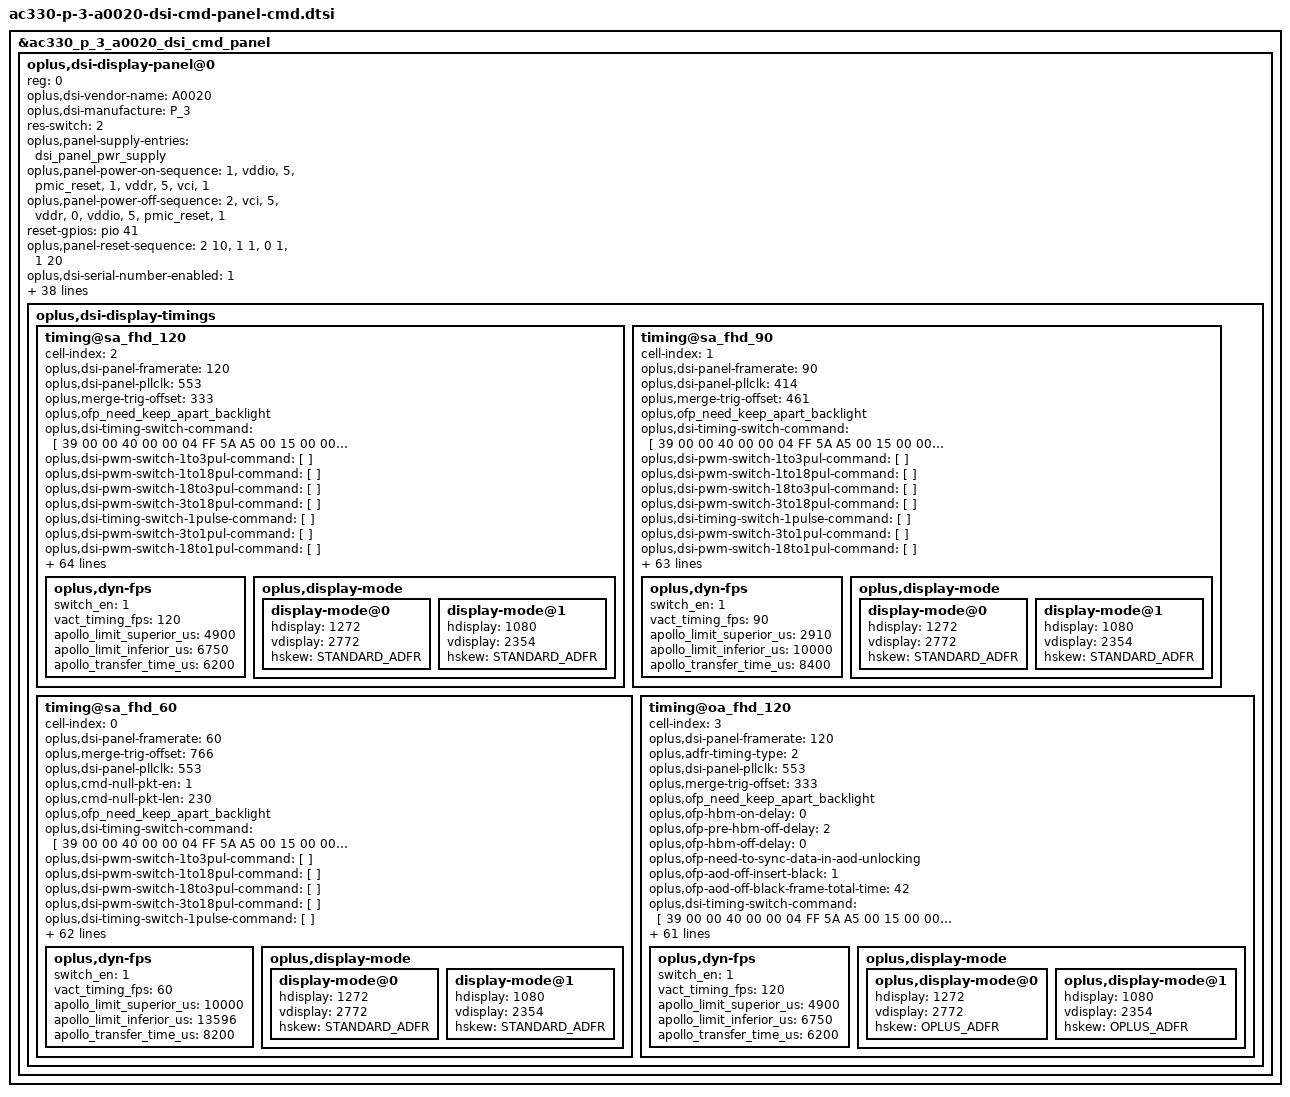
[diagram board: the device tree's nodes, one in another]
&ac330_p_3_a0020_dsi_cmd_panel {
	oplus,dsi-display-panel@0 {
		reg = <0>;
		oplus,dsi-vendor-name = "A0020";
		oplus,dsi-manufacture = "P_3";
		oplus,dsi-display-timings {
			timing@sa_fhd_120 {
				cell-index = <2>;
				oplus,dsi-panel-framerate = <120>;
				oplus,dsi-panel-pllclk = <553>;
				oplus,merge-trig-offset = <333>;
				//oplus,cmd-null-pkt-en = <1>;
				//oplus,cmd-null-pkt-len = <0>;
				/* OPLUS_FEATURE_DISPLAY_ONSCREENFINGERPRINT */
				oplus,ofp_need_keep_apart_backlight;
				/*oplus,ofp-hbm-on-delay = <0>;
				oplus,ofp-pre-hbm-off-delay = <2>;
				oplus,ofp-hbm-off-delay = <0>;
				oplus,ofp-need-to-sync-data-in-aod-unlocking;
				oplus,ofp-aod-off-insert-black = <1>;
				oplus,ofp-aod-off-black-frame-total-time = <42>;*/
				#include "ac330-p-3-a0020-dsi-cmd-panel-common.dtsi"
				oplus,dsi-timing-switch-command = [//Switch To 120Hz normal
					39 00 00 40 00 00 04 FF 5A A5 00
					15 00 00 40 00 00 02 60 00
					15 00 00 40 00 00 02 7D 00
					39 00 00 40 00 00 04 FF 5A A5 2D
					39 00 00 40 00 00 03 83 00 00
					15 00 00 40 00 00 02 F2 00
					39 00 00 00 00 00 04 FF 5A A5 00
				];
				oplus,dsi-pwm-switch-1to3pul-command = [
				];
				oplus,dsi-pwm-switch-1to18pul-command = [
				];
				oplus,dsi-pwm-switch-18to3pul-command = [
				];
				oplus,dsi-pwm-switch-3to18pul-command = [
				];
				oplus,dsi-timing-switch-1pulse-command = [
				];
				oplus,dsi-pwm-switch-3to1pul-command = [
				];
				oplus,dsi-pwm-switch-18to1pul-command = [
				];
				oplus,dsi-on-command = [
					//OTP Don’t reload
					39 00 00 00 00 00 04 FF 5A A5 08
					15 00 00 00 00 00 02 C8 62

					39 00 00 00 00 00 04 FF 5A A5 07
					15 00 00 00 00 00 02 8A 01
					39 00 00 00 00 00 03 8B 21 E0
					39 00 00 00 00 00 64 81 00 00 00 00 00 12 00 00 ab 30 80 0a d4 04 f8 00 16 02 7c 02 7c 02 00 02 59 00 20 02 2e 00 08 00 0d 04 f4 03 ed 18 00 10 f0 07 10 20 00 06 0f 0f 33 0e 1c 2a 38 46 54 62 69 70 77 79 7b 7d 7e 02 02 22 00 2a 40 2a be 3a fc 3a fa 3a f8 3b 38 3b 78 3b b6 4b b6 4b f4 4b f4 6c 34 84 74 00 00 00 00 00 00
					//Ycrcb
					15 00 00 00 00 00 02 91 03
					//VINIT3 SKIP
					39 00 00 00 00 00 04 FF 5A A5 51
					39 00 00 00 00 00 06 A0 98 A9 A8 A8 22
					15 00 00 00 00 00 02 FE 22
					15 00 00 00 00 00 02 00 00
					39 00 00 00 00 00 06 A1 A8 A7 7A 74 22
					15 00 00 00 00 00 02 FE 22
					15 00 00 00 00 00 02 00 00
					39 00 00 00 00 00 06 A2 71 6A 6A 72 22
					15 00 00 00 00 00 02 FE 22
					15 00 00 00 00 00 02 00 00
					//VINIT2 SKIP
					39 00 00 00 00 00 04 FF 5A A5 52
					39 00 00 00 00 00 06 C0 7C D2 9E 47 01
					15 00 00 00 00 00 02 FE 00
					15 00 00 00 00 00 02 00 00
					39 00 00 00 00 00 06 C1 48 48 5C 64 00
					15 00 00 00 00 00 02 FE 00
					15 00 00 00 00 00 02 00 00
					39 00 00 00 00 00 06 C2 5E 52 50 53 00
					15 00 00 00 00 00 02 FE 00
					15 00 00 00 00 00 02 00 00
					//DDIC RCN config
					39 00 00 40 00 00 04 FF 5A A5 16
					39 00 00 40 00 00 05 80 38 00 2D 00
					39 00 00 40 00 00 05 81 A7 00 52 00
					39 00 00 40 00 00 05 82 2F 00 ED 00
					39 00 00 40 00 00 05 83 A9 00 87 00
					39 00 00 40 00 00 05 84 65 00 43 00
					39 00 00 40 00 00 05 85 32 00 10 00
					39 00 00 40 00 00 05 86 1F 00 FF 00
					39 00 00 40 00 00 05 87 EE 00 DE 00
					39 00 00 40 00 00 05 88 CD 00 CC 00
					39 00 00 40 00 00 05 89 BB 00 CA 00
					39 00 00 40 00 00 05 8A BA 00 AA 00
					39 00 00 40 00 00 05 8B A9 00 99 00
					39 00 00 40 00 00 05 8C 98 00 98 00
					39 00 00 40 00 00 05 8D 97 00 88 00
					39 00 00 40 00 00 05 8E 87 00 77 00
					39 00 00 40 00 00 05 8F 77 00 77 00
					39 00 00 40 00 00 05 90 66 00 76 00
					39 00 00 40 00 00 05 91 66 00 65 00
					39 00 00 40 00 00 05 92 66 00 56 00
					39 00 00 40 00 00 05 93 55 00 55 00
					39 00 00 40 00 00 05 94 55 00 45 00
					39 00 00 40 00 00 05 95 54 00 54 00
					39 00 00 40 00 00 05 96 54 00 44 00
					39 00 00 40 00 00 05 97 44 00 44 00
					39 00 00 40 00 00 05 98 43 00 44 00
					39 00 00 40 00 00 05 99 34 00 24 00
					39 00 00 40 00 00 05 9A 33 00 43 00
					39 00 00 40 00 00 05 9B 33 00 33 00
					39 00 00 40 00 00 05 9C 33 00 32 00
					39 00 00 40 00 00 05 9D 32 00 32 00
					39 00 00 40 00 00 05 9E 32 00 32 00
					39 00 00 40 00 00 05 9F 31 00 22 00
					39 00 00 40 00 00 05 A0 32 00 22 00
					39 00 00 40 00 00 05 A1 22 00 21 00
					39 00 00 40 00 00 05 A2 21 00 22 00
					39 00 00 40 00 00 05 A3 11 00 20 00
					39 00 00 40 00 00 05 A4 22 00 12 00
					39 00 00 40 00 00 05 A5 02 00 12 00
					39 00 00 40 00 00 05 A6 12 00 01 00
					39 00 00 40 00 00 05 A7 12 00 10 00
					39 00 00 40 00 00 05 A8 11 00 21 00
					39 00 00 40 00 00 05 A9 11 00 11 00
					39 00 00 40 00 00 05 AA 10 00 11 00
					39 00 00 40 00 00 05 AB 11 00 00 00
					39 00 00 40 00 00 05 AC 10 00 01 00
					39 00 00 40 00 00 05 AD 01 00 01 00
					39 00 00 40 00 00 05 AE 10 00 11 00
					39 00 00 40 00 00 05 AF 00 00 10 00
					39 00 00 40 00 00 05 B0 00 00 10 00
					39 00 00 40 00 00 05 B1 01 00 01 00
					39 00 00 40 00 00 05 B2 00 00 10 00
					39 00 00 40 00 00 05 B3 10 00 10 00
					39 00 00 40 00 00 05 B4 01 00 00 00
					39 00 00 40 00 00 05 B5 01 00 00 00
					39 00 00 40 00 00 05 B6 00 00 00 00
					39 00 00 40 00 00 05 B7 10 00 01 00
					39 00 00 40 00 00 05 B8 00 00 10 00
					39 00 00 40 00 00 05 B9 00 00 10 00
					39 00 00 40 00 00 05 BA 00 00 00 00
					39 00 00 40 00 00 05 BB 10 00 00 00
					39 00 00 40 00 00 05 BC 00 00 10 00
					39 00 00 40 00 00 05 BD 00 00 00 00
					39 00 00 40 00 00 05 BE 00 00 00 00
					39 00 00 40 00 00 04 FF 5A A5 17
					39 00 00 40 00 00 05 80 00 00 00 00
					39 00 00 40 00 00 05 81 00 00 00 00
					39 00 00 40 00 00 05 82 00 00 00 00
					39 00 00 40 00 00 05 83 00 00 00 00
					39 00 00 40 00 00 05 84 00 00 00 00
					39 00 00 40 00 00 05 85 00 00 00 00
					39 00 00 40 00 00 05 86 00 00 00 01
					39 00 00 40 00 00 05 87 01 01 01 10
					39 00 00 40 00 00 05 88 10 11 01 10
					39 00 00 40 00 00 05 89 01 10 11 11
					39 00 00 40 00 00 05 8A 11 01 11 12
					39 00 00 40 00 00 05 8B 11 01 11 12
					39 00 00 40 00 00 05 8C 11 21 12 12
					39 00 00 40 00 00 05 8D 12 12 11 21
					39 00 00 40 00 00 05 8E 22 22 21 22
					39 00 00 40 00 00 05 8F 22 32 22 22
					39 00 00 40 00 00 05 90 22 32 32 33
					39 00 00 40 00 00 05 91 23 32 33 32
					39 00 00 40 00 00 05 92 43 33 34 33
					39 00 00 40 00 00 05 93 43 44 34 34
					39 00 00 40 00 00 05 94 44 54 44 54
					39 00 00 40 00 00 05 95 45 54 55 55
					39 00 00 40 00 00 05 96 64 65 66 56
					39 00 00 40 00 00 05 97 66 66 76 76
					39 00 00 40 00 00 05 98 77 87 87 78
					39 00 00 40 00 00 05 99 97 98 99 99
					39 00 00 40 00 00 05 9A 9A AA AB BB
					39 00 00 40 00 00 05 9B BC CC DD DE
					39 00 00 40 00 00 05 9C EF E0 01 12
					39 00 00 40 00 00 05 9D 23 54 56 79
					39 00 00 40 00 00 05 9E AC E0 13 48
					39 00 00 40 00 00 05 9F C0 61 13 48
					15 00 00 40 00 00 02 A0 8E
					15 00 00 40 00 00 02 A1 D0
					15 00 00 40 00 00 02 A2 FB
					15 00 00 40 00 00 02 A3 FC
					15 00 00 40 00 00 02 A4 2F
					15 00 00 40 00 00 02 A5 FC
					39 00 00 40 00 00 10 A6 05 04 04 03 03 04 03 03 03 03 03 02 02 02 02
					15 00 00 40 00 00 02 A8 18
					15 00 00 40 00 00 02 A9 03
					15 00 00 40 00 00 02 AA 00
					15 00 00 40 00 00 02 AB 00
					15 00 00 40 00 00 02 AC 00
					15 00 00 40 00 00 02 AD 00
					15 00 00 40 00 00 02 AE 00
					39 00 00 40 00 00 07 EC 00 00 00 00 00 00
					15 00 00 40 00 00 02 AF 04
					15 00 00 40 00 00 02 B0 0A
					15 00 00 40 00 00 02 B1 1A
					15 00 00 40 00 00 02 B2 19
					15 00 00 40 00 00 02 B3 09
					15 00 00 40 00 00 02 B4 03
					39 00 00 40 00 00 07 EC 00 00 00 00 00 00
					15 00 00 40 00 00 02 C0 00
					15 00 00 40 00 00 02 C1 00
					15 00 00 40 00 00 02 C2 00
					15 00 00 40 00 00 02 C3 00
					15 00 00 40 00 00 02 C4 00
					15 00 00 40 00 00 02 C5 00
					15 00 00 40 00 00 02 C6 00
					15 00 00 40 00 00 02 C7 33
					15 00 00 40 00 00 02 CA 08
					15 00 00 40 00 00 02 CB 80
					15 00 00 40 00 00 02 CC 05
					15 00 00 40 00 00 02 CD 03
					15 00 00 40 00 00 02 CE 08
					15 00 00 40 00 00 02 CF 05
					15 00 00 40 00 00 02 D0 7F
					15 00 00 40 00 00 02 D1 2C
					15 00 00 40 00 00 02 D2 80
					15 00 00 40 00 00 02 D3 0D
					15 00 00 40 00 00 02 D4 07
					15 00 00 40 00 00 02 D5 0E
					15 00 00 40 00 00 02 D6 03
					15 00 00 40 00 00 02 D7 14
					15 00 00 40 00 00 02 D8 A0
					15 00 00 40 00 00 02 E7 21
					15 00 00 40 00 00 02 E8 20
					15 00 00 40 00 00 02 E9 30
					15 00 00 40 00 00 02 EA 03
					39 00 00 40 00 00 03 EF 00 00
					15 00 00 40 00 00 02 F1 70
					39 00 00 00 00 00 06 F8 05 00 80 00 00

					//CTB ON
					39 00 00 00 00 00 04 FF 5A A5 31
					15 00 00 00 00 00 02 A0 A3
					//CCTC ON
					39 00 00 00 00 00 04 FF 5A A5 07
					15 00 00 00 00 00 02 E5 05

					39 00 00 00 00 00 04 FF 5A A5 06
					//scramble disable
					15 00 00 00 00 00 02 A0 00
					//set para.num
					15 00 00 00 00 00 02 AB 03
					15 00 00 00 00 00 02 AE 12
					//Page 21
					39 00 00 00 00 00 04 FF 5A A5 21
					//flash reload enable
					15 00 00 00 00 00 02 A4 18
					//Page 0
					39 00 00 00 00 00 04 FF 5A A5 00
					//Skip frame Enable
					15 00 00 00 00 00 02 5E 01
					//Normal = 120Hz
					15 00 00 00 00 00 02 60 00
					//AOD in = 30Hz
					15 00 00 00 00 00 02 61 07
					//TE On
					15 00 00 00 00 00 02 35 00
					//BC On, Dimming Off
					15 00 00 00 00 00 02 53 20
					//12-bit DBV,前两位输出normal的dbv，后两位为AOD的dbv
					39 00 00 00 00 00 05 51 00 00 07 FF
					39 00 00 00 00 00 04 FF 5A A5 20
					15 00 00 00 00 00 02 BC 07
					39 00 00 40 00 00 04 FF 5A A5 2D
					39 00 00 40 00 00 03 83 77 00
					15 00 00 40 00 00 02 97 03
					39 00 00 40 00 00 03 98 03 00
					39 00 00 40 00 00 03 99 0B 00
					39 00 00 40 00 00 03 9A 17 00
					39 00 00 40 00 00 03 9B 77 00
					39 00 00 40 00 00 05 A0 00 01 00 00
					39 00 00 40 00 00 05 A1 02 00 00 00
					39 00 00 40 00 00 03 83 00 00
					//spr config
					39 00 00 40 00 00 04 FF 5A A5 14
					39 00 00 40 00 00 07 A3 00 04 00 04 70 80
					//LVD on
					39 00 00 00 00 00 04 FF 5A A5 05
					15 00 00 00 00 00 02 83 03
					15 00 00 00 00 00 02 84 03
					15 00 00 00 00 00 02 AA 94
					15 00 00 00 00 00 02 AB C9
					15 00 00 00 00 00 02 AC 05
					39 00 00 00 00 00 04 FF 5A A5 08
					15 00 00 00 00 00 02 B0 55
					39 00 00 00 00 00 04 FF 5A A5 1C
					39 00 00 00 00 00 03 FD 00 94
					15 00 00 00 00 00 02 E1 A2
					39 00 00 00 00 00 03 FD 00 00
					39 00 00 00 00 00 04 FF 5A A5 08
					15 00 00 00 00 00 02 B0 00
					//page 00
					39 00 00 00 00 00 04 FF 5A A5 00

					15 00 00 00 78 00 02 11 00

					15 00 00 00 14 00 02 29 00
				];

				oplus,dsi-on-t0-command = [
					//OTP Don’t reload
					39 00 00 00 00 00 04 FF 5A A5 08
					15 00 00 00 00 00 02 C8 62

					39 00 00 00 00 00 04 FF 5A A5 07
					15 00 00 00 00 00 02 8A 01
					39 00 00 00 00 00 03 8B 21 E0
					39 00 00 00 00 00 64 81 00 00 00 00 00 12 00 00 ab 30 80 0a d4 04 f8 00 16 02 7c 02 7c 02 00 02 59 00 20 02 2e 00 08 00 0d 04 f4 03 ed 18 00 10 f0 07 10 20 00 06 0f 0f 33 0e 1c 2a 38 46 54 62 69 70 77 79 7b 7d 7e 02 02 22 00 2a 40 2a be 3a fc 3a fa 3a f8 3b 38 3b 78 3b b6 4b b6 4b f4 4b f4 6c 34 84 74 00 00 00 00 00 00
					//Ycrcb
					15 00 00 00 00 00 02 91 03
					//VINIT3 SKIP
					39 00 00 00 00 00 04 FF 5A A5 51
					39 00 00 00 00 00 06 A0 98 A9 A8 A8 22
					15 00 00 00 00 00 02 FE 22
					15 00 00 00 00 00 02 00 00
					39 00 00 00 00 00 06 A1 A8 A7 7A 74 22
					15 00 00 00 00 00 02 FE 22
					15 00 00 00 00 00 02 00 00
					39 00 00 00 00 00 06 A2 71 6A 6A 72 22
					15 00 00 00 00 00 02 FE 22
					15 00 00 00 00 00 02 00 00
					//VINIT2 SKIP
					39 00 00 00 00 00 04 FF 5A A5 52
					39 00 00 00 00 00 06 C0 7C D2 9E 47 01
					15 00 00 00 00 00 02 FE 00
					15 00 00 00 00 00 02 00 00
					39 00 00 00 00 00 06 C1 48 48 5C 64 00
					15 00 00 00 00 00 02 FE 00
					15 00 00 00 00 00 02 00 00
					39 00 00 00 00 00 06 C2 5E 52 50 53 00
					15 00 00 00 00 00 02 FE 00
					15 00 00 00 00 00 02 00 00
					//DDIC RCN config
					39 00 00 40 00 00 04 FF 5A A5 16
					39 00 00 40 00 00 05 80 38 00 2D 00
					39 00 00 40 00 00 05 81 A7 00 52 00
					39 00 00 40 00 00 05 82 2F 00 ED 00
					39 00 00 40 00 00 05 83 A9 00 87 00
					39 00 00 40 00 00 05 84 65 00 43 00
					39 00 00 40 00 00 05 85 32 00 10 00
					39 00 00 40 00 00 05 86 1F 00 FF 00
					39 00 00 40 00 00 05 87 EE 00 DE 00
					39 00 00 40 00 00 05 88 CD 00 CC 00
					39 00 00 40 00 00 05 89 BB 00 CA 00
					39 00 00 40 00 00 05 8A BA 00 AA 00
					39 00 00 40 00 00 05 8B A9 00 99 00
					39 00 00 40 00 00 05 8C 98 00 98 00
					39 00 00 40 00 00 05 8D 97 00 88 00
					39 00 00 40 00 00 05 8E 87 00 77 00
					39 00 00 40 00 00 05 8F 77 00 77 00
					39 00 00 40 00 00 05 90 66 00 76 00
					39 00 00 40 00 00 05 91 66 00 65 00
					39 00 00 40 00 00 05 92 66 00 56 00
					39 00 00 40 00 00 05 93 55 00 55 00
					39 00 00 40 00 00 05 94 55 00 45 00
					39 00 00 40 00 00 05 95 54 00 54 00
					39 00 00 40 00 00 05 96 54 00 44 00
					39 00 00 40 00 00 05 97 44 00 44 00
					39 00 00 40 00 00 05 98 43 00 44 00
					39 00 00 40 00 00 05 99 34 00 24 00
					39 00 00 40 00 00 05 9A 33 00 43 00
					39 00 00 40 00 00 05 9B 33 00 33 00
					39 00 00 40 00 00 05 9C 33 00 32 00
					39 00 00 40 00 00 05 9D 32 00 32 00
					39 00 00 40 00 00 05 9E 32 00 32 00
					39 00 00 40 00 00 05 9F 31 00 22 00
					39 00 00 40 00 00 05 A0 32 00 22 00
					39 00 00 40 00 00 05 A1 22 00 21 00
					39 00 00 40 00 00 05 A2 21 00 22 00
					39 00 00 40 00 00 05 A3 11 00 20 00
					39 00 00 40 00 00 05 A4 22 00 12 00
					39 00 00 40 00 00 05 A5 02 00 12 00
					39 00 00 40 00 00 05 A6 12 00 01 00
					39 00 00 40 00 00 05 A7 12 00 10 00
					39 00 00 40 00 00 05 A8 11 00 21 00
					39 00 00 40 00 00 05 A9 11 00 11 00
					39 00 00 40 00 00 05 AA 10 00 11 00
					39 00 00 40 00 00 05 AB 11 00 00 00
					39 00 00 40 00 00 05 AC 10 00 01 00
					39 00 00 40 00 00 05 AD 01 00 01 00
					39 00 00 40 00 00 05 AE 10 00 11 00
					39 00 00 40 00 00 05 AF 00 00 10 00
					39 00 00 40 00 00 05 B0 00 00 10 00
					39 00 00 40 00 00 05 B1 01 00 01 00
					39 00 00 40 00 00 05 B2 00 00 10 00
					39 00 00 40 00 00 05 B3 10 00 10 00
					39 00 00 40 00 00 05 B4 01 00 00 00
					39 00 00 40 00 00 05 B5 01 00 00 00
					39 00 00 40 00 00 05 B6 00 00 00 00
					39 00 00 40 00 00 05 B7 10 00 01 00
					39 00 00 40 00 00 05 B8 00 00 10 00
					39 00 00 40 00 00 05 B9 00 00 10 00
					39 00 00 40 00 00 05 BA 00 00 00 00
					39 00 00 40 00 00 05 BB 10 00 00 00
					39 00 00 40 00 00 05 BC 00 00 10 00
					39 00 00 40 00 00 05 BD 00 00 00 00
					39 00 00 40 00 00 05 BE 00 00 00 00
					39 00 00 40 00 00 04 FF 5A A5 17
					39 00 00 40 00 00 05 80 00 00 00 00
					39 00 00 40 00 00 05 81 00 00 00 00
					39 00 00 40 00 00 05 82 00 00 00 00
					39 00 00 40 00 00 05 83 00 00 00 00
					39 00 00 40 00 00 05 84 00 00 00 00
					39 00 00 40 00 00 05 85 00 00 00 00
					39 00 00 40 00 00 05 86 00 00 00 01
					39 00 00 40 00 00 05 87 01 01 01 10
					39 00 00 40 00 00 05 88 10 11 01 10
					39 00 00 40 00 00 05 89 01 10 11 11
					39 00 00 40 00 00 05 8A 11 01 11 12
					39 00 00 40 00 00 05 8B 11 01 11 12
					39 00 00 40 00 00 05 8C 11 21 12 12
					39 00 00 40 00 00 05 8D 12 12 11 21
					39 00 00 40 00 00 05 8E 22 22 21 22
					39 00 00 40 00 00 05 8F 22 32 22 22
					39 00 00 40 00 00 05 90 22 32 32 33
					39 00 00 40 00 00 05 91 23 32 33 32
					39 00 00 40 00 00 05 92 43 33 34 33
					39 00 00 40 00 00 05 93 43 44 34 34
					39 00 00 40 00 00 05 94 44 54 44 54
					39 00 00 40 00 00 05 95 45 54 55 55
					39 00 00 40 00 00 05 96 64 65 66 56
					39 00 00 40 00 00 05 97 66 66 76 76
					39 00 00 40 00 00 05 98 77 87 87 78
					39 00 00 40 00 00 05 99 97 98 99 99
					39 00 00 40 00 00 05 9A 9A AA AB BB
					39 00 00 40 00 00 05 9B BC CC DD DE
					39 00 00 40 00 00 05 9C EF E0 01 12
					39 00 00 40 00 00 05 9D 23 54 56 79
					39 00 00 40 00 00 05 9E AC E0 13 48
					39 00 00 40 00 00 05 9F C0 61 13 48
					15 00 00 40 00 00 02 A0 8E
					15 00 00 40 00 00 02 A1 D0
					15 00 00 40 00 00 02 A2 FB
					15 00 00 40 00 00 02 A3 FC
					15 00 00 40 00 00 02 A4 2F
					15 00 00 40 00 00 02 A5 FC
					39 00 00 40 00 00 10 A6 05 04 04 03 03 04 03 03 03 03 03 02 02 02 02
					15 00 00 40 00 00 02 A8 18
					15 00 00 40 00 00 02 A9 03
					15 00 00 40 00 00 02 AA 00
					15 00 00 40 00 00 02 AB 00
					15 00 00 40 00 00 02 AC 00
					15 00 00 40 00 00 02 AD 00
					15 00 00 40 00 00 02 AE 00
					39 00 00 40 00 00 07 EC 00 00 00 00 00 00
					15 00 00 40 00 00 02 AF 04
					15 00 00 40 00 00 02 B0 0A
					15 00 00 40 00 00 02 B1 1A
					15 00 00 40 00 00 02 B2 19
					15 00 00 40 00 00 02 B3 09
					15 00 00 40 00 00 02 B4 03
					39 00 00 40 00 00 07 EC 00 00 00 00 00 00
					15 00 00 40 00 00 02 C0 00
					15 00 00 40 00 00 02 C1 00
					15 00 00 40 00 00 02 C2 00
					15 00 00 40 00 00 02 C3 00
					15 00 00 40 00 00 02 C4 00
					15 00 00 40 00 00 02 C5 00
					15 00 00 40 00 00 02 C6 00
					15 00 00 40 00 00 02 C7 33
					15 00 00 40 00 00 02 CA 08
					15 00 00 40 00 00 02 CB 80
					15 00 00 40 00 00 02 CC 05
					15 00 00 40 00 00 02 CD 03
					15 00 00 40 00 00 02 CE 08
					15 00 00 40 00 00 02 CF 05
					15 00 00 40 00 00 02 D0 7F
					15 00 00 40 00 00 02 D1 2C
					15 00 00 40 00 00 02 D2 80
					15 00 00 40 00 00 02 D3 0D
					15 00 00 40 00 00 02 D4 07
					15 00 00 40 00 00 02 D5 0E
					15 00 00 40 00 00 02 D6 03
					15 00 00 40 00 00 02 D7 14
					15 00 00 40 00 00 02 D8 A0
					15 00 00 40 00 00 02 E7 21
					15 00 00 40 00 00 02 E8 20
					15 00 00 40 00 00 02 E9 30
					15 00 00 40 00 00 02 EA 03
					39 00 00 40 00 00 03 EF 00 00
					15 00 00 40 00 00 02 F1 70
					39 00 00 00 00 00 06 F8 05 00 80 00 00

					//CTB ON
					39 00 00 00 00 00 04 FF 5A A5 31
					15 00 00 00 00 00 02 A0 A3
					//CCTC ON
					39 00 00 00 00 00 04 FF 5A A5 07
					15 00 00 00 00 00 02 E5 05

					39 00 00 00 00 00 04 FF 5A A5 06
					//scramble disable
					15 00 00 00 00 00 02 A0 00
					//set para.num
					15 00 00 00 00 00 02 AB 03
					15 00 00 00 00 00 02 AE 12
					//Page 21
					39 00 00 00 00 00 04 FF 5A A5 21
					//flash reload enable
					15 00 00 00 00 00 02 A4 18
					//Page 0
					39 00 00 00 00 00 04 FF 5A A5 00
					//Skip frame Enable
					15 00 00 00 00 00 02 5E 01
					//Normal = 120Hz
					15 00 00 00 00 00 02 60 00
					//AOD in = 30Hz
					15 00 00 00 00 00 02 61 07
					//TE On
					15 00 00 00 00 00 02 35 00
					//BC On, Dimming Off
					15 00 00 00 00 00 02 53 20
					//12-bit DBV,前两位输出normal的dbv，后两位为AOD的dbv
					39 00 00 00 00 00 05 51 00 00 07 FF
					39 00 00 00 00 00 04 FF 5A A5 20
					15 00 00 00 00 00 02 BC 07

					39 00 00 00 00 00 04 FF 5A A5 2F
					39 00 00 00 00 00 02 99 E4
					39 00 00 00 00 00 07 80 06 FE 08 72 0A 3C
					39 00 00 00 00 00 07 81 0D 90 0D A7 10 8C
					39 00 00 00 00 00 07 82 0D FC 0E 14 11 10
					39 00 00 00 00 00 07 83 0F 18 0E D0 12 24
					39 00 00 00 00 00 07 84 10 B8 0F E0 13 BC
					39 00 00 00 00 00 07 85 11 FC 10 F4 15 2C
					39 00 00 00 00 00 07 86 12 A8 11 94 15 FC
					39 00 00 00 00 00 07 87 13 F4 12 C4 17 8C
					39 00 00 00 00 00 07 88 14 F8 13 BC 18 C8
					39 00 00 00 00 00 07 89 16 78 15 28 1A 94
					39 00 00 00 00 00 07 8A 17 AC 16 50 1C 00
					39 00 00 00 00 00 07 8B 19 6C 17 FC 1E 14
					39 00 00 00 00 00 07 8C 1B 38 19 B0 20 38
					39 00 00 00 00 00 07 8D 1D 54 1B A4 22 A8
					39 00 00 00 00 00 07 8E 1F 30 1D 60 24 D0
					39 00 00 00 00 00 07 8F 20 70 1E 90 26 50
					39 00 00 00 00 00 07 90 21 CC 1F D0 27 F0
					39 00 00 00 00 00 07 91 23 50 21 34 29 C0
					39 00 00 00 00 00 07 92 25 4C 23 08 2C 2C
					39 00 00 00 00 00 07 93 27 44 24 CC 2E 8C
					39 00 00 00 00 00 07 94 28 30 25 9C 2F B4
					39 00 00 00 00 00 07 95 29 84 26 E0 31 74
					39 00 00 00 00 00 07 96 2B 0C 28 4C 33 78
					39 00 00 00 00 00 07 97 2D 78 2A 70 36 A0
					39 00 00 00 00 00 02 99 00
					//spr config
					39 00 00 40 00 00 04 FF 5A A5 14
					39 00 00 40 00 00 07 A3 00 04 00 04 70 80
					//LVD on
					39 00 00 00 00 00 04 FF 5A A5 05
					15 00 00 00 00 00 02 83 03
					15 00 00 00 00 00 02 84 03
					15 00 00 00 00 00 02 AA 94
					15 00 00 00 00 00 02 AB C9
					15 00 00 00 00 00 02 AC 05
					39 00 00 00 00 00 04 FF 5A A5 08
					15 00 00 00 00 00 02 B0 55
					39 00 00 00 00 00 04 FF 5A A5 1C
					39 00 00 00 00 00 03 FD 00 94
					15 00 00 00 00 00 02 E1 A2
					39 00 00 00 00 00 03 FD 00 00
					39 00 00 00 00 00 04 FF 5A A5 08
					15 00 00 00 00 00 02 B0 00
					//page 00
					39 00 00 00 00 00 04 FF 5A A5 00

					15 00 00 00 78 00 02 11 00
					15 00 00 00 14 00 02 29 00
				];


				oplus,dsi-aod-off-command = [
					39 00 00 40 00 00 04 FF 5A A5 08
					39 00 00 40 00 00 02 98 02
					39 00 00 40 00 00 04 FF 5A A5 4F
					39 00 00 40 00 00 02 81 06
					39 00 00 40 00 00 02 88 78
					39 00 00 40 00 00 04 FF 5A A5 05
					39 00 00 40 00 00 02 AE 94
					39 00 00 40 00 00 02 AF DF
					39 00 00 40 00 00 02 B1 9F
					39 00 00 40 00 00 02 B2 DF
					39 00 00 40 00 00 04 C2 2F 20 37
					39 00 00 40 00 00 03 C4 32 3E
					39 00 00 40 00 00 04 FF 5A A5 00
					39 00 00 40 00 00 02 38 00
					39 00 00 40 00 00 04 FF 5A A5 4F
					39 00 00 40 00 00 02 8A 78
					39 00 00 40 00 00 04 FF 5A A5 05
					39 00 00 40 00 00 02 AE 92
					39 00 00 40 00 00 02 AF DA
					39 00 00 40 00 00 02 B1 9B
					39 00 00 40 00 00 02 B2 DB
					39 00 00 40 00 00 04 C2 37 20 37
					39 00 00 40 00 00 03 C4 3E 3E
					39 00 00 40 00 00 04 FF 5A A5 08
					39 00 00 40 00 00 02 98 A6
					39 00 00 40 00 00 04 FF 5A A5 00
					39 00 00 40 00 00 02 00 00
					39 00 00 40 00 00 04 FF 5A A5 4F
					39 00 00 40 00 00 02 8B 78
					39 00 00 00 00 00 03 51 00 00
				];
				oplus,dsi-panel-aod-off-insert-black-command = [
					39 00 00 40 00 00 04 FF 5A A5 08
					39 00 00 40 00 00 02 98 02
					39 00 00 40 00 00 04 FF 5A A5 4F
					39 00 00 40 00 00 02 81 06
					39 00 00 40 00 00 02 88 78
					39 00 00 40 00 00 04 FF 5A A5 05
					39 00 00 40 00 00 02 AE 94
					39 00 00 40 00 00 02 AF DF
					39 00 00 40 00 00 02 B1 9F
					39 00 00 40 00 00 02 B2 DF
					39 00 00 40 00 00 04 C2 2F 20 37
					39 00 00 40 00 00 03 C4 32 3E
					39 00 00 40 00 00 04 FF 5A A5 00
					39 00 00 40 00 00 02 38 00
					39 00 00 40 00 00 04 FF 5A A5 4F
					39 00 00 40 00 00 02 8A 78
					39 00 00 40 00 00 04 FF 5A A5 05
					39 00 00 40 00 00 02 AE 92
					39 00 00 40 00 00 02 AF DA
					39 00 00 40 00 00 02 B1 9B
					39 00 00 40 00 00 02 B2 DB
					39 00 00 40 00 00 04 C2 37 20 37
					39 00 00 40 00 00 03 C4 3E 3E
					39 00 00 40 00 00 04 FF 5A A5 08
					39 00 00 40 00 00 02 98 A6
					39 00 00 40 00 00 04 FF 5A A5 00
					39 00 00 40 00 00 02 00 00
					39 00 00 40 00 00 04 FF 5A A5 4F
					39 00 00 40 00 00 02 8B 78
					39 00 00 00 00 00 03 51 00 00
				];
				oplus,dsi-lhbm-pressed-icon-on-command = [
					39 00 00 40 00 00 04 FF 5A A5 00
					39 00 00 40 00 00 02 6E 03
					39 00 00 40 00 00 02 96 09
					39 00 00 40 00 00 02 97 E3
					39 00 00 40 00 00 02 98 02
					39 00 00 40 00 00 02 99 7C
					39 00 00 00 00 00 07 2C 00 00 00 00 00 00
				];
				oplus,dsi-lhbm-pressed-icon-on-pwm-command = [

				];
				oplus,dsi-adfr-min-fps-120hz-command = [
					39 00 00 40 00 00 04 FF 5A A5 2D
					39 00 00 40 00 00 03 83 77 00
					15 00 00 40 00 00 02 97 03
					39 00 00 40 00 00 03 98 03 00
					39 00 00 40 00 00 03 99 0B 00
					39 00 00 40 00 00 03 9A 17 00
					39 00 00 40 00 00 03 9B 77 00
					39 00 00 40 00 00 05 A0 00 01 00 00
					39 00 00 40 00 00 05 A1 02 00 00 00
					39 00 00 40 00 00 03 83 00 00
					39 00 00 00 00 00 04 FF 5A A5 00
				];
				oplus,dsi-adfr-min-fps-60hz-command = [
					39 00 00 40 00 00 04 FF 5A A5 2D
					39 00 00 40 00 00 03 83 77 00
					15 00 00 40 00 00 02 97 03
					39 00 00 40 00 00 03 98 03 00
					39 00 00 40 00 00 03 99 0B 00
					39 00 00 40 00 00 03 9A 17 00
					39 00 00 40 00 00 03 9B 77 00
					39 00 00 40 00 00 05 A0 00 01 00 00
					39 00 00 40 00 00 05 A1 02 00 00 00
					39 00 00 40 00 00 03 83 01 00
					39 00 00 00 00 00 04 FF 5A A5 00
				];
				oplus,dsi-adfr-min-fps-30hz-command = [
					39 00 00 40 00 00 04 FF 5A A5 2D
					39 00 00 40 00 00 03 83 77 00
					15 00 00 40 00 00 02 97 03
					39 00 00 40 00 00 03 98 03 00
					39 00 00 40 00 00 03 99 0B 00
					39 00 00 40 00 00 03 9A 17 00
					39 00 00 40 00 00 03 9B 77 00
					39 00 00 40 00 00 05 A0 00 01 00 00
					39 00 00 40 00 00 05 A1 02 00 00 00
					39 00 00 40 00 00 03 83 03 00
					39 00 00 00 00 00 04 FF 5A A5 00
				];
				oplus,dsi-adfr-min-fps-20hz-command = [
				];
				oplus,dsi-adfr-min-fps-10hz-command = [
					39 00 00 40 00 00 04 FF 5A A5 2D
					39 00 00 40 00 00 03 83 77 00
					15 00 00 40 00 00 02 97 03
					39 00 00 40 00 00 03 98 03 00
					39 00 00 40 00 00 03 99 0B 00
					39 00 00 40 00 00 03 9A 17 00
					39 00 00 40 00 00 03 9B 77 00
					39 00 00 40 00 00 05 A0 00 01 00 00
					39 00 00 40 00 00 05 A1 02 00 00 00
					39 00 00 40 00 00 03 83 0B 00
					39 00 00 00 00 00 04 FF 5A A5 00
				];
				oplus,dsi-adfr-min-fps-5hz-command = [
				];
				oplus,dsi-adfr-min-fps-1hz-command = [
					39 00 00 40 00 00 04 FF 5A A5 2D
					39 00 00 40 00 00 03 83 77 00
					15 00 00 40 00 00 02 97 03
					39 00 00 40 00 00 03 98 03 00
					39 00 00 40 00 00 03 99 0B 00
					39 00 00 40 00 00 03 9A 17 00
					39 00 00 40 00 00 03 9B 77 00
					39 00 00 40 00 00 05 A0 00 01 00 00
					39 00 00 40 00 00 05 A1 02 00 00 00
					39 00 00 40 00 00 03 83 77 00
					39 00 00 00 00 00 04 FF 5A A5 00
				];

				oplus,dsi-timing-switch-command-state = "dsi_hs_mode";
				oplus,dsi-pwm-switch-1to3pul-command-state = "dsi_hs_mode";
				oplus,dsi-pwm-switch-1to18pul-command-state = "dsi_hs_mode";
				oplus,dsi-pwm-switch-18to3pul-command-state = "dsi_hs_mode";
				oplus,dsi-pwm-switch-3to18pul-command-state = "dsi_hs_mode";
				oplus,dsi-timing-switch-1pulse-command-state = "dsi_hs_mode";
				oplus,dsi-pwm-switch-3to1pul-command-state = "dsi_hs_mode";
				oplus,dsi-pwm-switch-18to1pul-command-state = "dsi_hs_mode";
				oplus,dsi-on-command-state = "dsi_lp_mode";
				oplus,dsi-on-t0-command-state = "dsi_lp_mode";
				oplus,dsi-aod-off-command-state = "dsi_ls_mode";
				oplus,dsi-panel-aod-off-insert-black-command-state = "dsi_ls_mode";
				oplus,dsi-lhbm-pressed-icon-on-command-state = "dsi_hs_mode";
				oplus,dsi-lhbm-pressed-icon-on-pwm-command-state = "dsi_hs_mode";
				oplus,dsi-adfr-min-fps-120hz-command-state = "dsi_hs_mode";
				oplus,dsi-adfr-min-fps-60hz-command-state = "dsi_hs_mode";
				oplus,dsi-adfr-min-fps-30hz-command-state = "dsi_hs_mode";
				oplus,dsi-adfr-min-fps-20hz-command-state = "dsi_hs_mode";
				oplus,dsi-adfr-min-fps-10hz-command-state = "dsi_hs_mode";
				oplus,dsi-adfr-min-fps-5hz-command-state = "dsi_hs_mode";
				oplus,dsi-adfr-min-fps-1hz-command-state = "dsi_hs_mode";

				oplus,dsc-params-entries = <&dsc_params>;
/*				oplus,phy-timcon {
					hs-trail = <14>;
					clk-trail = <15>;
				};*/
				oplus,dyn-fps {
					switch_en = <1>;
					vact_timing_fps = <120>;
					apollo_limit_superior_us = <4900>;
					apollo_limit_inferior_us = <6750>;
					apollo_transfer_time_us = <6200>;
				};
				oplus,display-mode {
					display-mode@0 {
						hdisplay = <1272>;
						vdisplay = <2772>;
/*						fhd-hfp = <9>;
						fhd-hsa = <2>;
						fhd-hbp = <21>;
						fhd-vfp = <52>;
						fhd-vsa = <14>;
						fhd-vbp = <22>;*/
						hskew = <STANDARD_ADFR>;
					};
					display-mode@1 {
						hdisplay = <1080>;
						vdisplay = <2354>;
/*						fhd-hfp = <9>;
						fhd-hsa = <2>;
						fhd-hbp = <21>;
						fhd-vfp = <52>;
						fhd-vsa = <14>;
						fhd-vbp = <22>;*/
						hskew = <STANDARD_ADFR>;
					};
				};
			};

			timing@sa_fhd_90 {
				cell-index = <1>;
				oplus,dsi-panel-framerate = <90>;
				oplus,dsi-panel-pllclk = <414>;
				oplus,merge-trig-offset = <461>;
				/* OPLUS_FEATURE_DISPLAY_ONSCREENFINGERPRINT */
				oplus,ofp_need_keep_apart_backlight;
				/*oplus,ofp-hbm-on-delay = <0>;
				oplus,ofp-pre-hbm-off-delay = <9>;
				oplus,ofp-hbm-off-delay = <0>;
				oplus,ofp-need-to-sync-data-in-aod-unlocking;
				oplus,ofp-aod-off-insert-black = <2>;
				oplus,ofp-aod-off-black-frame-total-time = <45>;*/
				#include "ac330-p-3-a0020-dsi-cmd-panel-common.dtsi"
				oplus,dsi-timing-switch-command = [//Switch To 90Hz normal
					39 00 00 40 00 00 04 FF 5A A5 00
					15 00 00 40 00 00 02 60 02
					15 00 00 40 00 00 02 7D 00
					39 00 00 40 00 00 04 FF 5A A5 2D
					39 00 00 40 00 00 03 85 00 00
					39 00 00 00 00 00 04 FF 5A A5 00
				];
				oplus,dsi-pwm-switch-1to3pul-command = [
				];
				oplus,dsi-pwm-switch-1to18pul-command = [
				];
				oplus,dsi-pwm-switch-18to3pul-command = [
				];
				oplus,dsi-pwm-switch-3to18pul-command = [
				];
				oplus,dsi-timing-switch-1pulse-command = [
				];
				oplus,dsi-pwm-switch-3to1pul-command = [
				];
				oplus,dsi-pwm-switch-18to1pul-command = [
				];
				oplus,dsi-on-command = [
					//OTP Don’t reload
					39 00 00 00 00 00 04 FF 5A A5 08
					15 00 00 00 00 00 02 C8 62

					39 00 00 00 00 00 04 FF 5A A5 07
					15 00 00 00 00 00 02 8A 01
					39 00 00 00 00 00 03 8B 21 E0
					39 00 00 00 00 00 64 81 00 00 00 00 00 12 00 00 ab 30 80 0a d4 04 f8 00 16 02 7c 02 7c 02 00 02 59 00 20 02 2e 00 08 00 0d 04 f4 03 ed 18 00 10 f0 07 10 20 00 06 0f 0f 33 0e 1c 2a 38 46 54 62 69 70 77 79 7b 7d 7e 02 02 22 00 2a 40 2a be 3a fc 3a fa 3a f8 3b 38 3b 78 3b b6 4b b6 4b f4 4b f4 6c 34 84 74 00 00 00 00 00 00
					//Ycrcb
					15 00 00 00 00 00 02 91 03
					//VINIT3 SKIP
					39 00 00 00 00 00 04 FF 5A A5 51
					39 00 00 00 00 00 06 A0 98 A9 A8 A8 22
					15 00 00 00 00 00 02 FE 22
					15 00 00 00 00 00 02 00 00
					39 00 00 00 00 00 06 A1 A8 A7 7A 74 22
					15 00 00 00 00 00 02 FE 22
					15 00 00 00 00 00 02 00 00
					39 00 00 00 00 00 06 A2 71 6A 6A 72 22
					15 00 00 00 00 00 02 FE 22
					15 00 00 00 00 00 02 00 00
					//VINIT2 SKIP
					39 00 00 00 00 00 04 FF 5A A5 52
					39 00 00 00 00 00 06 C0 7C D2 9E 47 01
					15 00 00 00 00 00 02 FE 00
					15 00 00 00 00 00 02 00 00
					39 00 00 00 00 00 06 C1 48 48 5C 64 00
					15 00 00 00 00 00 02 FE 00
					15 00 00 00 00 00 02 00 00
					39 00 00 00 00 00 06 C2 5E 52 50 53 00
					15 00 00 00 00 00 02 FE 00
					15 00 00 00 00 00 02 00 00
					//DDIC RCN config
					39 00 00 40 00 00 04 FF 5A A5 16
					39 00 00 40 00 00 05 80 38 00 2D 00
					39 00 00 40 00 00 05 81 A7 00 52 00
					39 00 00 40 00 00 05 82 2F 00 ED 00
					39 00 00 40 00 00 05 83 A9 00 87 00
					39 00 00 40 00 00 05 84 65 00 43 00
					39 00 00 40 00 00 05 85 32 00 10 00
					39 00 00 40 00 00 05 86 1F 00 FF 00
					39 00 00 40 00 00 05 87 EE 00 DE 00
					39 00 00 40 00 00 05 88 CD 00 CC 00
					39 00 00 40 00 00 05 89 BB 00 CA 00
					39 00 00 40 00 00 05 8A BA 00 AA 00
					39 00 00 40 00 00 05 8B A9 00 99 00
					39 00 00 40 00 00 05 8C 98 00 98 00
					39 00 00 40 00 00 05 8D 97 00 88 00
					39 00 00 40 00 00 05 8E 87 00 77 00
					39 00 00 40 00 00 05 8F 77 00 77 00
					39 00 00 40 00 00 05 90 66 00 76 00
					39 00 00 40 00 00 05 91 66 00 65 00
					39 00 00 40 00 00 05 92 66 00 56 00
					39 00 00 40 00 00 05 93 55 00 55 00
					39 00 00 40 00 00 05 94 55 00 45 00
					39 00 00 40 00 00 05 95 54 00 54 00
					39 00 00 40 00 00 05 96 54 00 44 00
					39 00 00 40 00 00 05 97 44 00 44 00
					39 00 00 40 00 00 05 98 43 00 44 00
					39 00 00 40 00 00 05 99 34 00 24 00
					39 00 00 40 00 00 05 9A 33 00 43 00
					39 00 00 40 00 00 05 9B 33 00 33 00
					39 00 00 40 00 00 05 9C 33 00 32 00
					39 00 00 40 00 00 05 9D 32 00 32 00
					39 00 00 40 00 00 05 9E 32 00 32 00
					39 00 00 40 00 00 05 9F 31 00 22 00
					39 00 00 40 00 00 05 A0 32 00 22 00
					39 00 00 40 00 00 05 A1 22 00 21 00
					39 00 00 40 00 00 05 A2 21 00 22 00
					39 00 00 40 00 00 05 A3 11 00 20 00
					39 00 00 40 00 00 05 A4 22 00 12 00
					39 00 00 40 00 00 05 A5 02 00 12 00
					39 00 00 40 00 00 05 A6 12 00 01 00
					39 00 00 40 00 00 05 A7 12 00 10 00
					39 00 00 40 00 00 05 A8 11 00 21 00
					39 00 00 40 00 00 05 A9 11 00 11 00
					39 00 00 40 00 00 05 AA 10 00 11 00
					39 00 00 40 00 00 05 AB 11 00 00 00
					39 00 00 40 00 00 05 AC 10 00 01 00
					39 00 00 40 00 00 05 AD 01 00 01 00
					39 00 00 40 00 00 05 AE 10 00 11 00
					39 00 00 40 00 00 05 AF 00 00 10 00
					39 00 00 40 00 00 05 B0 00 00 10 00
					39 00 00 40 00 00 05 B1 01 00 01 00
					39 00 00 40 00 00 05 B2 00 00 10 00
					39 00 00 40 00 00 05 B3 10 00 10 00
					39 00 00 40 00 00 05 B4 01 00 00 00
					39 00 00 40 00 00 05 B5 01 00 00 00
					39 00 00 40 00 00 05 B6 00 00 00 00
					39 00 00 40 00 00 05 B7 10 00 01 00
					39 00 00 40 00 00 05 B8 00 00 10 00
					39 00 00 40 00 00 05 B9 00 00 10 00
					39 00 00 40 00 00 05 BA 00 00 00 00
					39 00 00 40 00 00 05 BB 10 00 00 00
					39 00 00 40 00 00 05 BC 00 00 10 00
					39 00 00 40 00 00 05 BD 00 00 00 00
					39 00 00 40 00 00 05 BE 00 00 00 00
					39 00 00 40 00 00 04 FF 5A A5 17
					39 00 00 40 00 00 05 80 00 00 00 00
					39 00 00 40 00 00 05 81 00 00 00 00
					39 00 00 40 00 00 05 82 00 00 00 00
					39 00 00 40 00 00 05 83 00 00 00 00
					39 00 00 40 00 00 05 84 00 00 00 00
					39 00 00 40 00 00 05 85 00 00 00 00
					39 00 00 40 00 00 05 86 00 00 00 01
					39 00 00 40 00 00 05 87 01 01 01 10
					39 00 00 40 00 00 05 88 10 11 01 10
					39 00 00 40 00 00 05 89 01 10 11 11
					39 00 00 40 00 00 05 8A 11 01 11 12
					39 00 00 40 00 00 05 8B 11 01 11 12
					39 00 00 40 00 00 05 8C 11 21 12 12
					39 00 00 40 00 00 05 8D 12 12 11 21
					39 00 00 40 00 00 05 8E 22 22 21 22
					39 00 00 40 00 00 05 8F 22 32 22 22
					39 00 00 40 00 00 05 90 22 32 32 33
					39 00 00 40 00 00 05 91 23 32 33 32
					39 00 00 40 00 00 05 92 43 33 34 33
					39 00 00 40 00 00 05 93 43 44 34 34
					39 00 00 40 00 00 05 94 44 54 44 54
					39 00 00 40 00 00 05 95 45 54 55 55
					39 00 00 40 00 00 05 96 64 65 66 56
					39 00 00 40 00 00 05 97 66 66 76 76
					39 00 00 40 00 00 05 98 77 87 87 78
					39 00 00 40 00 00 05 99 97 98 99 99
					39 00 00 40 00 00 05 9A 9A AA AB BB
					39 00 00 40 00 00 05 9B BC CC DD DE
					39 00 00 40 00 00 05 9C EF E0 01 12
					39 00 00 40 00 00 05 9D 23 54 56 79
					39 00 00 40 00 00 05 9E AC E0 13 48
					39 00 00 40 00 00 05 9F C0 61 13 48
					15 00 00 40 00 00 02 A0 8E
					15 00 00 40 00 00 02 A1 D0
					15 00 00 40 00 00 02 A2 FB
					15 00 00 40 00 00 02 A3 FC
					15 00 00 40 00 00 02 A4 2F
					15 00 00 40 00 00 02 A5 FC
					39 00 00 40 00 00 10 A6 05 04 04 03 03 04 03 03 03 03 03 02 02 02 02
					15 00 00 40 00 00 02 A8 18
					15 00 00 40 00 00 02 A9 03
					15 00 00 40 00 00 02 AA 00
					15 00 00 40 00 00 02 AB 00
					15 00 00 40 00 00 02 AC 00
					15 00 00 40 00 00 02 AD 00
					15 00 00 40 00 00 02 AE 00
					39 00 00 40 00 00 07 EC 00 00 00 00 00 00
					15 00 00 40 00 00 02 AF 04
					15 00 00 40 00 00 02 B0 0A
					15 00 00 40 00 00 02 B1 1A
					15 00 00 40 00 00 02 B2 19
					15 00 00 40 00 00 02 B3 09
					15 00 00 40 00 00 02 B4 03
					39 00 00 40 00 00 07 EC 00 00 00 00 00 00
					15 00 00 40 00 00 02 C0 00
					15 00 00 40 00 00 02 C1 00
					15 00 00 40 00 00 02 C2 00
					15 00 00 40 00 00 02 C3 00
					15 00 00 40 00 00 02 C4 00
					15 00 00 40 00 00 02 C5 00
					15 00 00 40 00 00 02 C6 00
					15 00 00 40 00 00 02 C7 33
					15 00 00 40 00 00 02 CA 08
					15 00 00 40 00 00 02 CB 80
					15 00 00 40 00 00 02 CC 05
					15 00 00 40 00 00 02 CD 03
					15 00 00 40 00 00 02 CE 08
					15 00 00 40 00 00 02 CF 05
					15 00 00 40 00 00 02 D0 7F
					15 00 00 40 00 00 02 D1 2C
					15 00 00 40 00 00 02 D2 80
					15 00 00 40 00 00 02 D3 0D
					15 00 00 40 00 00 02 D4 07
					15 00 00 40 00 00 02 D5 0E
					15 00 00 40 00 00 02 D6 03
					15 00 00 40 00 00 02 D7 14
					15 00 00 40 00 00 02 D8 A0
					15 00 00 40 00 00 02 E7 21
					15 00 00 40 00 00 02 E8 20
					15 00 00 40 00 00 02 E9 30
					15 00 00 40 00 00 02 EA 03
					39 00 00 40 00 00 03 EF 00 00
					15 00 00 40 00 00 02 F1 70
					39 00 00 00 00 00 06 F8 05 00 80 00 00

					//CTB ON
					39 00 00 00 00 00 04 FF 5A A5 31
					15 00 00 00 00 00 02 A0 A3
					//CCTC ON
					39 00 00 00 00 00 04 FF 5A A5 07
					15 00 00 00 00 00 02 E5 05

					39 00 00 00 00 00 04 FF 5A A5 06
					//scramble disable
					15 00 00 00 00 00 02 A0 00
					//set para.num
					15 00 00 00 00 00 02 AB 03
					15 00 00 00 00 00 02 AE 12
					//Page 21
					39 00 00 00 00 00 04 FF 5A A5 21
					//flash reload enable
					15 00 00 00 00 00 02 A4 18
					//Page 0
					39 00 00 00 00 00 04 FF 5A A5 00
					//Skip frame Enable
					15 00 00 00 00 00 02 5E 01
					//Normal = 90Hz
					15 00 00 00 00 00 02 60 02
					//AOD in = 30Hz
					15 00 00 00 00 00 02 61 07
					//TE On
					15 00 00 00 00 00 02 35 00
					//BC On, Dimming Off
					15 00 00 00 00 00 02 53 20
					//12-bit DBV,前两位输出normal的dbv，后两位为AOD的dbv
					39 00 00 00 00 00 05 51 00 00 07 FF
					39 00 00 00 00 00 04 FF 5A A5 20
					15 00 00 00 00 00 02 BC 07
					39 00 00 40 00 00 04 FF 5A A5 2D
					39 00 00 40 00 00 03 85 59 00
					15 00 00 40 00 00 02 B1 03
					39 00 00 40 00 00 03 B2 02 00
					39 00 00 40 00 00 03 B3 08 00
					39 00 00 40 00 00 03 B4 11 00
					39 00 00 40 00 00 03 B5 59 00
					39 00 00 40 00 00 03 BA 00 01
					39 00 00 40 00 00 03 BB 02 00
					39 00 00 40 00 00 03 85 00 00
					//spr config
					39 00 00 40 00 00 04 FF 5A A5 14
					39 00 00 40 00 00 07 A3 00 04 00 04 70 80
					//LVD on
					39 00 00 00 00 00 04 FF 5A A5 05
					15 00 00 00 00 00 02 83 03
					15 00 00 00 00 00 02 84 03
					15 00 00 00 00 00 02 AA 94
					15 00 00 00 00 00 02 AB C9
					15 00 00 00 00 00 02 AC 05
					39 00 00 00 00 00 04 FF 5A A5 08
					15 00 00 00 00 00 02 B0 55
					39 00 00 00 00 00 04 FF 5A A5 1C
					39 00 00 00 00 00 03 FD 00 94
					15 00 00 00 00 00 02 E1 A2
					39 00 00 00 00 00 03 FD 00 00
					39 00 00 00 00 00 04 FF 5A A5 08
					15 00 00 00 00 00 02 B0 00
					//page 00
					39 00 00 00 00 00 04 FF 5A A5 00
					15 00 00 00 78 00 02 11 00

					15 00 00 00 14 00 02 29 00
				];

				oplus,dsi-on-t0-command = [
					//OTP Don’t reload
					39 00 00 00 00 00 04 FF 5A A5 08
					15 00 00 00 00 00 02 C8 62

					39 00 00 00 00 00 04 FF 5A A5 07
					15 00 00 00 00 00 02 8A 01
					39 00 00 00 00 00 03 8B 21 E0
					39 00 00 00 00 00 64 81 00 00 00 00 00 12 00 00 ab 30 80 0a d4 04 f8 00 16 02 7c 02 7c 02 00 02 59 00 20 02 2e 00 08 00 0d 04 f4 03 ed 18 00 10 f0 07 10 20 00 06 0f 0f 33 0e 1c 2a 38 46 54 62 69 70 77 79 7b 7d 7e 02 02 22 00 2a 40 2a be 3a fc 3a fa 3a f8 3b 38 3b 78 3b b6 4b b6 4b f4 4b f4 6c 34 84 74 00 00 00 00 00 00
					//Ycrcb
					15 00 00 00 00 00 02 91 03
					//VINIT3 SKIP
					39 00 00 00 00 00 04 FF 5A A5 51
					39 00 00 00 00 00 06 A0 98 A9 A8 A8 22
					15 00 00 00 00 00 02 FE 22
					15 00 00 00 00 00 02 00 00
					39 00 00 00 00 00 06 A1 A8 A7 7A 74 22
					15 00 00 00 00 00 02 FE 22
					15 00 00 00 00 00 02 00 00
					39 00 00 00 00 00 06 A2 71 6A 6A 72 22
					15 00 00 00 00 00 02 FE 22
					15 00 00 00 00 00 02 00 00
					//VINIT2 SKIP
					39 00 00 00 00 00 04 FF 5A A5 52
					39 00 00 00 00 00 06 C0 7C D2 9E 47 01
					15 00 00 00 00 00 02 FE 00
					15 00 00 00 00 00 02 00 00
					39 00 00 00 00 00 06 C1 48 48 5C 64 00
					15 00 00 00 00 00 02 FE 00
					15 00 00 00 00 00 02 00 00
					39 00 00 00 00 00 06 C2 5E 52 50 53 00
					15 00 00 00 00 00 02 FE 00
					15 00 00 00 00 00 02 00 00
					//DDIC RCN config
					39 00 00 40 00 00 04 FF 5A A5 16
					39 00 00 40 00 00 05 80 38 00 2D 00
					39 00 00 40 00 00 05 81 A7 00 52 00
					39 00 00 40 00 00 05 82 2F 00 ED 00
					39 00 00 40 00 00 05 83 A9 00 87 00
					39 00 00 40 00 00 05 84 65 00 43 00
					39 00 00 40 00 00 05 85 32 00 10 00
					39 00 00 40 00 00 05 86 1F 00 FF 00
					39 00 00 40 00 00 05 87 EE 00 DE 00
					39 00 00 40 00 00 05 88 CD 00 CC 00
					39 00 00 40 00 00 05 89 BB 00 CA 00
					39 00 00 40 00 00 05 8A BA 00 AA 00
					39 00 00 40 00 00 05 8B A9 00 99 00
					39 00 00 40 00 00 05 8C 98 00 98 00
					39 00 00 40 00 00 05 8D 97 00 88 00
					39 00 00 40 00 00 05 8E 87 00 77 00
					39 00 00 40 00 00 05 8F 77 00 77 00
					39 00 00 40 00 00 05 90 66 00 76 00
					39 00 00 40 00 00 05 91 66 00 65 00
					39 00 00 40 00 00 05 92 66 00 56 00
					39 00 00 40 00 00 05 93 55 00 55 00
					39 00 00 40 00 00 05 94 55 00 45 00
					39 00 00 40 00 00 05 95 54 00 54 00
					39 00 00 40 00 00 05 96 54 00 44 00
					39 00 00 40 00 00 05 97 44 00 44 00
					39 00 00 40 00 00 05 98 43 00 44 00
					39 00 00 40 00 00 05 99 34 00 24 00
					39 00 00 40 00 00 05 9A 33 00 43 00
					39 00 00 40 00 00 05 9B 33 00 33 00
					39 00 00 40 00 00 05 9C 33 00 32 00
					39 00 00 40 00 00 05 9D 32 00 32 00
					39 00 00 40 00 00 05 9E 32 00 32 00
					39 00 00 40 00 00 05 9F 31 00 22 00
					39 00 00 40 00 00 05 A0 32 00 22 00
					39 00 00 40 00 00 05 A1 22 00 21 00
					39 00 00 40 00 00 05 A2 21 00 22 00
					39 00 00 40 00 00 05 A3 11 00 20 00
					39 00 00 40 00 00 05 A4 22 00 12 00
					39 00 00 40 00 00 05 A5 02 00 12 00
					39 00 00 40 00 00 05 A6 12 00 01 00
					39 00 00 40 00 00 05 A7 12 00 10 00
					39 00 00 40 00 00 05 A8 11 00 21 00
					39 00 00 40 00 00 05 A9 11 00 11 00
					39 00 00 40 00 00 05 AA 10 00 11 00
					39 00 00 40 00 00 05 AB 11 00 00 00
					39 00 00 40 00 00 05 AC 10 00 01 00
					39 00 00 40 00 00 05 AD 01 00 01 00
					39 00 00 40 00 00 05 AE 10 00 11 00
					39 00 00 40 00 00 05 AF 00 00 10 00
					39 00 00 40 00 00 05 B0 00 00 10 00
					39 00 00 40 00 00 05 B1 01 00 01 00
					39 00 00 40 00 00 05 B2 00 00 10 00
					39 00 00 40 00 00 05 B3 10 00 10 00
					39 00 00 40 00 00 05 B4 01 00 00 00
					39 00 00 40 00 00 05 B5 01 00 00 00
					39 00 00 40 00 00 05 B6 00 00 00 00
					39 00 00 40 00 00 05 B7 10 00 01 00
					39 00 00 40 00 00 05 B8 00 00 10 00
					39 00 00 40 00 00 05 B9 00 00 10 00
					39 00 00 40 00 00 05 BA 00 00 00 00
					39 00 00 40 00 00 05 BB 10 00 00 00
					39 00 00 40 00 00 05 BC 00 00 10 00
					39 00 00 40 00 00 05 BD 00 00 00 00
					39 00 00 40 00 00 05 BE 00 00 00 00
					39 00 00 40 00 00 04 FF 5A A5 17
					39 00 00 40 00 00 05 80 00 00 00 00
					39 00 00 40 00 00 05 81 00 00 00 00
					39 00 00 40 00 00 05 82 00 00 00 00
					39 00 00 40 00 00 05 83 00 00 00 00
					39 00 00 40 00 00 05 84 00 00 00 00
					39 00 00 40 00 00 05 85 00 00 00 00
					39 00 00 40 00 00 05 86 00 00 00 01
					39 00 00 40 00 00 05 87 01 01 01 10
					39 00 00 40 00 00 05 88 10 11 01 10
					39 00 00 40 00 00 05 89 01 10 11 11
					39 00 00 40 00 00 05 8A 11 01 11 12
					39 00 00 40 00 00 05 8B 11 01 11 12
					39 00 00 40 00 00 05 8C 11 21 12 12
					39 00 00 40 00 00 05 8D 12 12 11 21
					39 00 00 40 00 00 05 8E 22 22 21 22
					39 00 00 40 00 00 05 8F 22 32 22 22
					39 00 00 40 00 00 05 90 22 32 32 33
					39 00 00 40 00 00 05 91 23 32 33 32
					39 00 00 40 00 00 05 92 43 33 34 33
					39 00 00 40 00 00 05 93 43 44 34 34
					39 00 00 40 00 00 05 94 44 54 44 54
					39 00 00 40 00 00 05 95 45 54 55 55
					39 00 00 40 00 00 05 96 64 65 66 56
					39 00 00 40 00 00 05 97 66 66 76 76
					39 00 00 40 00 00 05 98 77 87 87 78
					39 00 00 40 00 00 05 99 97 98 99 99
					39 00 00 40 00 00 05 9A 9A AA AB BB
					39 00 00 40 00 00 05 9B BC CC DD DE
					39 00 00 40 00 00 05 9C EF E0 01 12
					39 00 00 40 00 00 05 9D 23 54 56 79
					39 00 00 40 00 00 05 9E AC E0 13 48
					39 00 00 40 00 00 05 9F C0 61 13 48
					15 00 00 40 00 00 02 A0 8E
					15 00 00 40 00 00 02 A1 D0
					15 00 00 40 00 00 02 A2 FB
					15 00 00 40 00 00 02 A3 FC
					15 00 00 40 00 00 02 A4 2F
					15 00 00 40 00 00 02 A5 FC
					39 00 00 40 00 00 10 A6 05 04 04 03 03 04 03 03 03 03 03 02 02 02 02
					15 00 00 40 00 00 02 A8 18
					15 00 00 40 00 00 02 A9 03
					15 00 00 40 00 00 02 AA 00
					15 00 00 40 00 00 02 AB 00
					15 00 00 40 00 00 02 AC 00
					15 00 00 40 00 00 02 AD 00
					15 00 00 40 00 00 02 AE 00
					39 00 00 40 00 00 07 EC 00 00 00 00 00 00
					15 00 00 40 00 00 02 AF 04
					15 00 00 40 00 00 02 B0 0A
					15 00 00 40 00 00 02 B1 1A
					15 00 00 40 00 00 02 B2 19
					15 00 00 40 00 00 02 B3 09
					15 00 00 40 00 00 02 B4 03
					39 00 00 40 00 00 07 EC 00 00 00 00 00 00
					15 00 00 40 00 00 02 C0 00
					15 00 00 40 00 00 02 C1 00
					15 00 00 40 00 00 02 C2 00
					15 00 00 40 00 00 02 C3 00
					15 00 00 40 00 00 02 C4 00
					15 00 00 40 00 00 02 C5 00
					15 00 00 40 00 00 02 C6 00
					15 00 00 40 00 00 02 C7 33
					15 00 00 40 00 00 02 CA 08
					15 00 00 40 00 00 02 CB 80
					15 00 00 40 00 00 02 CC 05
					15 00 00 40 00 00 02 CD 03
					15 00 00 40 00 00 02 CE 08
					15 00 00 40 00 00 02 CF 05
					15 00 00 40 00 00 02 D0 7F
					15 00 00 40 00 00 02 D1 2C
					15 00 00 40 00 00 02 D2 80
					15 00 00 40 00 00 02 D3 0D
					15 00 00 40 00 00 02 D4 07
					15 00 00 40 00 00 02 D5 0E
					15 00 00 40 00 00 02 D6 03
					15 00 00 40 00 00 02 D7 14
					15 00 00 40 00 00 02 D8 A0
					15 00 00 40 00 00 02 E7 21
					15 00 00 40 00 00 02 E8 20
					15 00 00 40 00 00 02 E9 30
					15 00 00 40 00 00 02 EA 03
					39 00 00 40 00 00 03 EF 00 00
					15 00 00 40 00 00 02 F1 70
					39 00 00 00 00 00 06 F8 05 00 80 00 00

					//CTB ON
					39 00 00 00 00 00 04 FF 5A A5 31
					15 00 00 00 00 00 02 A0 A3
					//CCTC ON
					39 00 00 00 00 00 04 FF 5A A5 07
					15 00 00 00 00 00 02 E5 05

					39 00 00 00 00 00 04 FF 5A A5 06
					//scramble disable
					15 00 00 00 00 00 02 A0 00
					//set para.num
					15 00 00 00 00 00 02 AB 03
					15 00 00 00 00 00 02 AE 12
					//Page 21
					39 00 00 00 00 00 04 FF 5A A5 21
					//flash reload enable
					15 00 00 00 00 00 02 A4 18
					//Page 0
					39 00 00 00 00 00 04 FF 5A A5 00
					//Skip frame Enable
					15 00 00 00 00 00 02 5E 01
					//Normal = 90Hz
					15 00 00 00 00 00 02 60 02
					//AOD in = 30Hz
					15 00 00 00 00 00 02 61 07
					//TE On
					15 00 00 00 00 00 02 35 00
					//BC On, Dimming Off
					15 00 00 00 00 00 02 53 20
					//12-bit DBV,前两位输出normal的dbv，后两位为AOD的dbv
					39 00 00 00 00 00 05 51 00 00 07 FF

					39 00 00 00 00 00 04 FF 5A A5 20
					15 00 00 00 00 00 02 BC 07
					39 00 00 00 00 00 04 FF 5A A5 2F
					39 00 00 00 00 00 02 99 E4
					39 00 00 00 00 00 07 80 06 FE 08 72 0A 3C
					39 00 00 00 00 00 07 81 0D 90 0D A7 10 8C
					39 00 00 00 00 00 07 82 0D FC 0E 14 11 10
					39 00 00 00 00 00 07 83 0F 18 0E D0 12 24
					39 00 00 00 00 00 07 84 10 B8 0F E0 13 BC
					39 00 00 00 00 00 07 85 11 FC 10 F4 15 2C
					39 00 00 00 00 00 07 86 12 A8 11 94 15 FC
					39 00 00 00 00 00 07 87 13 F4 12 C4 17 8C
					39 00 00 00 00 00 07 88 14 F8 13 BC 18 C8
					39 00 00 00 00 00 07 89 16 78 15 28 1A 94
					39 00 00 00 00 00 07 8A 17 AC 16 50 1C 00
					39 00 00 00 00 00 07 8B 19 6C 17 FC 1E 14
					39 00 00 00 00 00 07 8C 1B 38 19 B0 20 38
					39 00 00 00 00 00 07 8D 1D 54 1B A4 22 A8
					39 00 00 00 00 00 07 8E 1F 30 1D 60 24 D0
					39 00 00 00 00 00 07 8F 20 70 1E 90 26 50
					39 00 00 00 00 00 07 90 21 CC 1F D0 27 F0
					39 00 00 00 00 00 07 91 23 50 21 34 29 C0
					39 00 00 00 00 00 07 92 25 4C 23 08 2C 2C
					39 00 00 00 00 00 07 93 27 44 24 CC 2E 8C
					39 00 00 00 00 00 07 94 28 30 25 9C 2F B4
					39 00 00 00 00 00 07 95 29 84 26 E0 31 74
					39 00 00 00 00 00 07 96 2B 0C 28 4C 33 78
					39 00 00 00 00 00 07 97 2D 78 2A 70 36 A0
					39 00 00 00 00 00 02 99 00
					//spr config
					39 00 00 40 00 00 04 FF 5A A5 14
					39 00 00 40 00 00 07 A3 00 04 00 04 70 80
					//LVD on
					39 00 00 00 00 00 04 FF 5A A5 05
					15 00 00 00 00 00 02 83 03
					15 00 00 00 00 00 02 84 03
					15 00 00 00 00 00 02 AA 94
					15 00 00 00 00 00 02 AB C9
					15 00 00 00 00 00 02 AC 05
					39 00 00 00 00 00 04 FF 5A A5 08
					15 00 00 00 00 00 02 B0 55
					39 00 00 00 00 00 04 FF 5A A5 1C
					39 00 00 00 00 00 03 FD 00 94
					15 00 00 00 00 00 02 E1 A2
					39 00 00 00 00 00 03 FD 00 00
					39 00 00 00 00 00 04 FF 5A A5 08
					15 00 00 00 00 00 02 B0 00
					//page 00
					39 00 00 00 00 00 04 FF 5A A5 00
					15 00 00 00 78 00 02 11 00
					15 00 00 00 14 00 02 29 00
				];

				oplus,dsi-aod-off-command = [
					39 00 00 40 00 00 04 FF 5A A5 08
					39 00 00 40 00 00 02 98 02
					39 00 00 40 00 00 04 FF 5A A5 4F
					39 00 00 40 00 00 02 81 06
					39 00 00 40 00 00 02 88 78
					39 00 00 40 00 00 04 FF 5A A5 05
					39 00 00 40 00 00 02 AE 94
					39 00 00 40 00 00 02 AF DF
					39 00 00 40 00 00 02 B1 9F
					39 00 00 40 00 00 02 B2 DF
					39 00 00 40 00 00 04 C2 2F 20 37
					39 00 00 40 00 00 03 C4 32 3E
					39 00 00 40 00 00 04 FF 5A A5 00
					39 00 00 40 00 00 02 38 00
					39 00 00 40 00 00 04 FF 5A A5 4F
					39 00 00 40 00 00 02 8A 78
					39 00 00 40 00 00 04 FF 5A A5 05
					39 00 00 40 00 00 02 AE 92
					39 00 00 40 00 00 02 AF DA
					39 00 00 40 00 00 02 B1 9B
					39 00 00 40 00 00 02 B2 DB
					39 00 00 40 00 00 04 C2 37 20 37
					39 00 00 40 00 00 03 C4 3E 3E
					39 00 00 40 00 00 04 FF 5A A5 08
					39 00 00 40 00 00 02 98 A6
					39 00 00 40 00 00 04 FF 5A A5 00
					39 00 00 40 00 00 02 00 00
					39 00 00 40 00 00 04 FF 5A A5 4F
					39 00 00 40 00 00 02 8B 78
					39 00 00 00 00 00 03 51 00 00
				];
				oplus,dsi-panel-aod-off-insert-black-command = [
					39 00 00 40 00 00 04 FF 5A A5 08
					39 00 00 40 00 00 02 98 02
					39 00 00 40 00 00 04 FF 5A A5 4F
					39 00 00 40 00 00 02 81 06
					39 00 00 40 00 00 02 88 78
					39 00 00 40 00 00 04 FF 5A A5 05
					39 00 00 40 00 00 02 AE 94
					39 00 00 40 00 00 02 AF DF
					39 00 00 40 00 00 02 B1 9F
					39 00 00 40 00 00 02 B2 DF
					39 00 00 40 00 00 04 C2 2F 20 37
					39 00 00 40 00 00 03 C4 32 3E
					39 00 00 40 00 00 04 FF 5A A5 00
					39 00 00 40 00 00 02 38 00
					39 00 00 40 00 00 04 FF 5A A5 4F
					39 00 00 40 00 00 02 8A 78
					39 00 00 40 00 00 04 FF 5A A5 05
					39 00 00 40 00 00 02 AE 92
					39 00 00 40 00 00 02 AF DA
					39 00 00 40 00 00 02 B1 9B
					39 00 00 40 00 00 02 B2 DB
					39 00 00 40 00 00 04 C2 37 20 37
					39 00 00 40 00 00 03 C4 3E 3E
					39 00 00 40 00 00 04 FF 5A A5 08
					39 00 00 40 00 00 02 98 A6
					39 00 00 40 00 00 04 FF 5A A5 00
					39 00 00 40 00 00 02 00 00
					39 00 00 40 00 00 04 FF 5A A5 4F
					39 00 00 40 00 00 02 8B 78
					39 00 00 00 00 00 03 51 00 00
				];
				oplus,dsi-lhbm-pressed-icon-on-command = [
					39 00 00 40 00 00 04 FF 5A A5 00
					39 00 00 40 00 00 02 6E 03
					39 00 00 40 00 00 02 96 09
					39 00 00 40 00 00 02 97 E3
					39 00 00 40 00 00 02 98 02
					39 00 00 40 00 00 02 99 7C
					39 00 00 00 00 00 07 2C 00 00 00 00 00 00
				];
				oplus,dsi-lhbm-pressed-icon-on-pwm-command = [

				];
				oplus,dsi-adfr-min-fps-90hz-command = [
					39 00 00 40 00 00 04 FF 5A A5 2D
					39 00 00 40 00 00 03 85 59 00
					15 00 00 40 00 00 02 B1 03
					39 00 00 40 00 00 03 B2 02 00
					39 00 00 40 00 00 03 B3 08 00
					39 00 00 40 00 00 03 B4 11 00
					39 00 00 40 00 00 03 B5 59 00
					39 00 00 40 00 00 03 BA 00 01
					39 00 00 40 00 00 03 BB 02 00
					39 00 00 40 00 00 03 85 00 00
					39 00 00 00 00 00 04 FF 5A A5 00
				];
				oplus,dsi-adfr-min-fps-45hz-command = [
				];
				oplus,dsi-adfr-min-fps-30hz-command = [
					39 00 00 40 00 00 04 FF 5A A5 2D
					39 00 00 40 00 00 03 85 59 00
					15 00 00 40 00 00 02 B1 03
					39 00 00 40 00 00 03 B2 02 00
					39 00 00 40 00 00 03 B3 08 00
					39 00 00 40 00 00 03 B4 11 00
					39 00 00 40 00 00 03 B5 59 00
					39 00 00 40 00 00 03 BA 00 01
					39 00 00 40 00 00 03 BB 02 00
					39 00 00 40 00 00 03 85 02 00
					39 00 00 00 00 00 04 FF 5A A5 00
				];
				oplus,dsi-adfr-min-fps-15hz-command = [
				];
				oplus,dsi-adfr-min-fps-10hz-command = [
					39 00 00 40 00 00 04 FF 5A A5 2D
					39 00 00 40 00 00 03 85 59 00
					15 00 00 40 00 00 02 B1 03
					39 00 00 40 00 00 03 B2 02 00
					39 00 00 40 00 00 03 B3 08 00
					39 00 00 40 00 00 03 B4 11 00
					39 00 00 40 00 00 03 B5 59 00
					39 00 00 40 00 00 03 BA 00 01
					39 00 00 40 00 00 03 BB 02 00
					39 00 00 40 00 00 03 85 08 00
					39 00 00 00 00 00 04 FF 5A A5 00
				];
				oplus,dsi-adfr-min-fps-5hz-command = [
				];
				oplus,dsi-adfr-min-fps-1hz-command = [
					39 00 00 40 00 00 04 FF 5A A5 2D
					39 00 00 40 00 00 03 85 59 00
					15 00 00 40 00 00 02 B1 03
					39 00 00 40 00 00 03 B2 02 00
					39 00 00 40 00 00 03 B3 08 00
					39 00 00 40 00 00 03 B4 11 00
					39 00 00 40 00 00 03 B5 59 00
					39 00 00 40 00 00 03 BA 00 01
					39 00 00 40 00 00 03 BB 02 00
					39 00 00 40 00 00 03 85 59 00
					39 00 00 00 00 00 04 FF 5A A5 00
				];

				oplus,dsi-timing-switch-command-state = "dsi_hs_mode";
				oplus,dsi-pwm-switch-1to3pul-command-state = "dsi_hs_mode";
				oplus,dsi-pwm-switch-1to18pul-command-state = "dsi_hs_mode";
				oplus,dsi-pwm-switch-18to3pul-command-state = "dsi_hs_mode";
				oplus,dsi-pwm-switch-3to18pul-command-state = "dsi_hs_mode";
				oplus,dsi-timing-switch-1pulse-command-state = "dsi_hs_mode";
				oplus,dsi-pwm-switch-3to1pul-command-state = "dsi_hs_mode";
				oplus,dsi-pwm-switch-18to1pul-command-state = "dsi_hs_mode";
				oplus,dsi-on-command-state = "dsi_lp_mode";
				oplus,dsi-on-t0-command-state = "dsi_lp_mode";
				oplus,dsi-aod-off-command-state = "dsi_ls_mode";
				oplus,dsi-panel-aod-off-insert-black-command-state = "dsi_ls_mode";
				oplus,dsi-lhbm-pressed-icon-on-command-state = "dsi_hs_mode";
				oplus,dsi-lhbm-pressed-icon-on-pwm-command-state = "dsi_hs_mode";
				oplus,dsi-adfr-min-fps-90hz-command-state = "dsi_hs_mode";
				oplus,dsi-adfr-min-fps-45hz-command-state = "dsi_hs_mode";
				oplus,dsi-adfr-min-fps-30hz-command-state = "dsi_hs_mode";
				oplus,dsi-adfr-min-fps-15hz-command-state = "dsi_hs_mode";
				oplus,dsi-adfr-min-fps-10hz-command-state = "dsi_hs_mode";
				oplus,dsi-adfr-min-fps-5hz-command-state = "dsi_hs_mode";
				oplus,dsi-adfr-min-fps-1hz-command-state = "dsi_hs_mode";

				oplus,dsc-params-entries = <&dsc_params>;
/*				oplus,phy-timcon {
					hs-trail = <14>;
					clk-trail = <15>;
				};*/
				oplus,dyn-fps {
					switch_en = <1>;
					vact_timing_fps = <90>;
					apollo_limit_superior_us = <2910>;
					apollo_limit_inferior_us = <10000>;
					apollo_transfer_time_us = <8400>;
				};
				oplus,display-mode {
					display-mode@0 {
						hdisplay = <1272>;
						vdisplay = <2772>;
/*						fhd-hfp = <9>;
						fhd-hsa = <2>;
						fhd-hbp = <21>;
						fhd-vfp = <52>;
						fhd-vsa = <14>;
						fhd-vbp = <22>;*/
						hskew = <STANDARD_ADFR>;
					};
					display-mode@1 {
						hdisplay = <1080>;
						vdisplay = <2354>;
/*						fhd-hfp = <9>;
						fhd-hsa = <2>;
						fhd-hbp = <21>;
						fhd-vfp = <52>;
						fhd-vsa = <14>;
						fhd-vbp = <22>;*/
						hskew = <STANDARD_ADFR>;
					};
				};
			};

			timing@sa_fhd_60 {
				cell-index = <0>;
				oplus,dsi-panel-framerate = <60>;
				oplus,merge-trig-offset = <766>;
				oplus,dsi-panel-pllclk = <553>;
				oplus,cmd-null-pkt-en = <1>;
				oplus,cmd-null-pkt-len = <230>;
				/* OPLUS_FEATURE_DISPLAY_ONSCREENFINGERPRINT */
				oplus,ofp_need_keep_apart_backlight;
				/*oplus,ofp-hbm-on-delay = <0>;
				oplus,ofp-pre-hbm-off-delay = <12>;
				oplus,ofp-hbm-off-delay = <0>;
				oplus,ofp-need-to-sync-data-in-aod-unlocking;
				oplus,ofp-aod-off-insert-black = <2>;
				oplus,ofp-aod-off-black-frame-total-time = <59>;*/
				#include "ac330-p-3-a0020-dsi-cmd-panel-common.dtsi"
				oplus,dsi-timing-switch-command = [//Switch To 60Hz normal
					39 00 00 40 00 00 04 FF 5A A5 00
					15 00 00 40 00 00 02 60 00
					15 00 00 40 00 00 02 7D 00
					39 00 00 40 00 00 04 FF 5A A5 2D
					39 00 00 40 00 00 03 83 01 00
					15 00 00 40 00 00 02 F2 01
					39 00 00 00 00 00 04 FF 5A A5 00
				];
				oplus,dsi-pwm-switch-1to3pul-command = [
				];
				oplus,dsi-pwm-switch-1to18pul-command = [
				];
				oplus,dsi-pwm-switch-18to3pul-command = [
				];
				oplus,dsi-pwm-switch-3to18pul-command = [
				];
				oplus,dsi-timing-switch-1pulse-command = [
				];
				oplus,dsi-pwm-switch-3to1pul-command = [
				];
				oplus,dsi-pwm-switch-18to1pul-command = [
				];
				oplus,dsi-on-command = [
					//OTP Don’t reload
					39 00 00 00 00 00 04 FF 5A A5 08
					15 00 00 00 00 00 02 C8 62

					39 00 00 00 00 00 04 FF 5A A5 07
					15 00 00 00 00 00 02 8A 01
					39 00 00 00 00 00 03 8B 21 E0
					39 00 00 00 00 00 64 81 00 00 00 00 00 12 00 00 ab 30 80 0a d4 04 f8 00 16 02 7c 02 7c 02 00 02 59 00 20 02 2e 00 08 00 0d 04 f4 03 ed 18 00 10 f0 07 10 20 00 06 0f 0f 33 0e 1c 2a 38 46 54 62 69 70 77 79 7b 7d 7e 02 02 22 00 2a 40 2a be 3a fc 3a fa 3a f8 3b 38 3b 78 3b b6 4b b6 4b f4 4b f4 6c 34 84 74 00 00 00 00 00 00
					//Ycrcb
					15 00 00 00 00 00 02 91 03
					//VINIT3 SKIP
					39 00 00 00 00 00 04 FF 5A A5 51
					39 00 00 00 00 00 06 A0 98 A9 A8 A8 22
					15 00 00 00 00 00 02 FE 22
					15 00 00 00 00 00 02 00 00
					39 00 00 00 00 00 06 A1 A8 A7 7A 74 22
					15 00 00 00 00 00 02 FE 22
					15 00 00 00 00 00 02 00 00
					39 00 00 00 00 00 06 A2 71 6A 6A 72 22
					15 00 00 00 00 00 02 FE 22
					15 00 00 00 00 00 02 00 00
					//VINIT2 SKIP
					39 00 00 00 00 00 04 FF 5A A5 52
					39 00 00 00 00 00 06 C0 7C D2 9E 47 01
					15 00 00 00 00 00 02 FE 00
					15 00 00 00 00 00 02 00 00
					39 00 00 00 00 00 06 C1 48 48 5C 64 00
					15 00 00 00 00 00 02 FE 00
					15 00 00 00 00 00 02 00 00
					39 00 00 00 00 00 06 C2 5E 52 50 53 00
					15 00 00 00 00 00 02 FE 00
					15 00 00 00 00 00 02 00 00
					//DDIC RCN config
					39 00 00 40 00 00 04 FF 5A A5 16
					39 00 00 40 00 00 05 80 38 00 2D 00
					39 00 00 40 00 00 05 81 A7 00 52 00
					39 00 00 40 00 00 05 82 2F 00 ED 00
					39 00 00 40 00 00 05 83 A9 00 87 00
					39 00 00 40 00 00 05 84 65 00 43 00
					39 00 00 40 00 00 05 85 32 00 10 00
					39 00 00 40 00 00 05 86 1F 00 FF 00
					39 00 00 40 00 00 05 87 EE 00 DE 00
					39 00 00 40 00 00 05 88 CD 00 CC 00
					39 00 00 40 00 00 05 89 BB 00 CA 00
					39 00 00 40 00 00 05 8A BA 00 AA 00
					39 00 00 40 00 00 05 8B A9 00 99 00
					39 00 00 40 00 00 05 8C 98 00 98 00
					39 00 00 40 00 00 05 8D 97 00 88 00
					39 00 00 40 00 00 05 8E 87 00 77 00
					39 00 00 40 00 00 05 8F 77 00 77 00
					39 00 00 40 00 00 05 90 66 00 76 00
					39 00 00 40 00 00 05 91 66 00 65 00
					39 00 00 40 00 00 05 92 66 00 56 00
					39 00 00 40 00 00 05 93 55 00 55 00
					39 00 00 40 00 00 05 94 55 00 45 00
					39 00 00 40 00 00 05 95 54 00 54 00
					39 00 00 40 00 00 05 96 54 00 44 00
					39 00 00 40 00 00 05 97 44 00 44 00
					39 00 00 40 00 00 05 98 43 00 44 00
					39 00 00 40 00 00 05 99 34 00 24 00
					39 00 00 40 00 00 05 9A 33 00 43 00
					39 00 00 40 00 00 05 9B 33 00 33 00
					39 00 00 40 00 00 05 9C 33 00 32 00
					39 00 00 40 00 00 05 9D 32 00 32 00
					39 00 00 40 00 00 05 9E 32 00 32 00
					39 00 00 40 00 00 05 9F 31 00 22 00
					39 00 00 40 00 00 05 A0 32 00 22 00
					39 00 00 40 00 00 05 A1 22 00 21 00
					39 00 00 40 00 00 05 A2 21 00 22 00
					39 00 00 40 00 00 05 A3 11 00 20 00
					39 00 00 40 00 00 05 A4 22 00 12 00
					39 00 00 40 00 00 05 A5 02 00 12 00
					39 00 00 40 00 00 05 A6 12 00 01 00
					39 00 00 40 00 00 05 A7 12 00 10 00
					39 00 00 40 00 00 05 A8 11 00 21 00
					39 00 00 40 00 00 05 A9 11 00 11 00
					39 00 00 40 00 00 05 AA 10 00 11 00
					39 00 00 40 00 00 05 AB 11 00 00 00
					39 00 00 40 00 00 05 AC 10 00 01 00
					39 00 00 40 00 00 05 AD 01 00 01 00
					39 00 00 40 00 00 05 AE 10 00 11 00
					39 00 00 40 00 00 05 AF 00 00 10 00
					39 00 00 40 00 00 05 B0 00 00 10 00
					39 00 00 40 00 00 05 B1 01 00 01 00
					39 00 00 40 00 00 05 B2 00 00 10 00
					39 00 00 40 00 00 05 B3 10 00 10 00
					39 00 00 40 00 00 05 B4 01 00 00 00
					39 00 00 40 00 00 05 B5 01 00 00 00
					39 00 00 40 00 00 05 B6 00 00 00 00
					39 00 00 40 00 00 05 B7 10 00 01 00
					39 00 00 40 00 00 05 B8 00 00 10 00
					39 00 00 40 00 00 05 B9 00 00 10 00
					39 00 00 40 00 00 05 BA 00 00 00 00
					39 00 00 40 00 00 05 BB 10 00 00 00
					39 00 00 40 00 00 05 BC 00 00 10 00
					39 00 00 40 00 00 05 BD 00 00 00 00
					39 00 00 40 00 00 05 BE 00 00 00 00
					39 00 00 40 00 00 04 FF 5A A5 17
					39 00 00 40 00 00 05 80 00 00 00 00
					39 00 00 40 00 00 05 81 00 00 00 00
					39 00 00 40 00 00 05 82 00 00 00 00
					39 00 00 40 00 00 05 83 00 00 00 00
					39 00 00 40 00 00 05 84 00 00 00 00
					39 00 00 40 00 00 05 85 00 00 00 00
					39 00 00 40 00 00 05 86 00 00 00 01
					39 00 00 40 00 00 05 87 01 01 01 10
					39 00 00 40 00 00 05 88 10 11 01 10
					39 00 00 40 00 00 05 89 01 10 11 11
					39 00 00 40 00 00 05 8A 11 01 11 12
					39 00 00 40 00 00 05 8B 11 01 11 12
					39 00 00 40 00 00 05 8C 11 21 12 12
					39 00 00 40 00 00 05 8D 12 12 11 21
					39 00 00 40 00 00 05 8E 22 22 21 22
					39 00 00 40 00 00 05 8F 22 32 22 22
					39 00 00 40 00 00 05 90 22 32 32 33
					39 00 00 40 00 00 05 91 23 32 33 32
					39 00 00 40 00 00 05 92 43 33 34 33
					39 00 00 40 00 00 05 93 43 44 34 34
					39 00 00 40 00 00 05 94 44 54 44 54
					39 00 00 40 00 00 05 95 45 54 55 55
					39 00 00 40 00 00 05 96 64 65 66 56
					39 00 00 40 00 00 05 97 66 66 76 76
					39 00 00 40 00 00 05 98 77 87 87 78
					39 00 00 40 00 00 05 99 97 98 99 99
					39 00 00 40 00 00 05 9A 9A AA AB BB
					39 00 00 40 00 00 05 9B BC CC DD DE
					39 00 00 40 00 00 05 9C EF E0 01 12
					39 00 00 40 00 00 05 9D 23 54 56 79
					39 00 00 40 00 00 05 9E AC E0 13 48
					39 00 00 40 00 00 05 9F C0 61 13 48
					15 00 00 40 00 00 02 A0 8E
					15 00 00 40 00 00 02 A1 D0
					15 00 00 40 00 00 02 A2 FB
					15 00 00 40 00 00 02 A3 FC
					15 00 00 40 00 00 02 A4 2F
					15 00 00 40 00 00 02 A5 FC
					39 00 00 40 00 00 10 A6 05 04 04 03 03 04 03 03 03 03 03 02 02 02 02
					15 00 00 40 00 00 02 A8 18
					15 00 00 40 00 00 02 A9 03
					15 00 00 40 00 00 02 AA 00
					15 00 00 40 00 00 02 AB 00
					15 00 00 40 00 00 02 AC 00
					15 00 00 40 00 00 02 AD 00
					15 00 00 40 00 00 02 AE 00
					39 00 00 40 00 00 07 EC 00 00 00 00 00 00
					15 00 00 40 00 00 02 AF 04
					15 00 00 40 00 00 02 B0 0A
					15 00 00 40 00 00 02 B1 1A
					15 00 00 40 00 00 02 B2 19
					15 00 00 40 00 00 02 B3 09
					15 00 00 40 00 00 02 B4 03
					39 00 00 40 00 00 07 EC 00 00 00 00 00 00
					15 00 00 40 00 00 02 C0 00
					15 00 00 40 00 00 02 C1 00
					15 00 00 40 00 00 02 C2 00
					15 00 00 40 00 00 02 C3 00
					15 00 00 40 00 00 02 C4 00
					15 00 00 40 00 00 02 C5 00
					15 00 00 40 00 00 02 C6 00
					15 00 00 40 00 00 02 C7 33
					15 00 00 40 00 00 02 CA 08
					15 00 00 40 00 00 02 CB 80
					15 00 00 40 00 00 02 CC 05
					15 00 00 40 00 00 02 CD 03
					15 00 00 40 00 00 02 CE 08
					15 00 00 40 00 00 02 CF 05
					15 00 00 40 00 00 02 D0 7F
					15 00 00 40 00 00 02 D1 2C
					15 00 00 40 00 00 02 D2 80
					15 00 00 40 00 00 02 D3 0D
					15 00 00 40 00 00 02 D4 07
					15 00 00 40 00 00 02 D5 0E
					15 00 00 40 00 00 02 D6 03
					15 00 00 40 00 00 02 D7 14
					15 00 00 40 00 00 02 D8 A0
					15 00 00 40 00 00 02 E7 21
					15 00 00 40 00 00 02 E8 20
					15 00 00 40 00 00 02 E9 30
					15 00 00 40 00 00 02 EA 03
					39 00 00 40 00 00 03 EF 00 00
					15 00 00 40 00 00 02 F1 70
					39 00 00 00 00 00 06 F8 05 00 80 00 00

					//CTB ON
					39 00 00 00 00 00 04 FF 5A A5 31
					15 00 00 00 00 00 02 A0 A3
					//CCTC ON
					39 00 00 00 00 00 04 FF 5A A5 07
					15 00 00 00 00 00 02 E5 05

					39 00 00 00 00 00 04 FF 5A A5 06
					//scramble disable
					15 00 00 00 00 00 02 A0 00
					//set para.num
					15 00 00 00 00 00 02 AB 03
					15 00 00 00 00 00 02 AE 12
					//Page 21
					39 00 00 00 00 00 04 FF 5A A5 21
					//flash reload enable
					15 00 00 00 00 00 02 A4 18
					//Page 0
					39 00 00 00 00 00 04 FF 5A A5 00
					//Skip frame Enable
					15 00 00 00 00 00 02 5E 01
					//Normal = 60Hz
					15 00 00 00 00 00 02 60 00
					39 00 00 00 00 00 04 FF 5A A5 2D
					39 00 00 00 00 00 03 83 01 00
					15 00 00 00 00 00 02 F2 01
					//Page 0
					39 00 00 00 00 00 04 FF 5A A5 00

					//AOD in = 30Hz
					15 00 00 00 00 00 02 61 07
					//TE On
					15 00 00 00 00 00 02 35 00
					//BC On, Dimming Off
					15 00 00 00 00 00 02 53 20
					//12-bit DBV,前两位输出normal的dbv，后两位为AOD的dbv
					39 00 00 00 00 00 05 51 00 00 07 FF
					39 00 00 00 00 00 04 FF 5A A5 20
					15 00 00 00 00 00 02 BC 07
					39 00 00 40 00 00 04 FF 5A A5 2D
					39 00 00 40 00 00 03 83 77 00
					15 00 00 40 00 00 02 97 03
					39 00 00 40 00 00 03 98 03 00
					39 00 00 40 00 00 03 99 0B 00
					39 00 00 40 00 00 03 9A 17 00
					39 00 00 40 00 00 03 9B 77 00
					39 00 00 40 00 00 05 A0 00 01 00 00
					39 00 00 40 00 00 05 A1 02 00 00 00
					39 00 00 40 00 00 03 83 01 00
					//spr config
					39 00 00 40 00 00 04 FF 5A A5 14
					39 00 00 40 00 00 07 A3 00 04 00 04 70 80
					//LVD on
					39 00 00 00 00 00 04 FF 5A A5 05
					15 00 00 00 00 00 02 83 03
					15 00 00 00 00 00 02 84 03
					15 00 00 00 00 00 02 AA 94
					15 00 00 00 00 00 02 AB C9
					15 00 00 00 00 00 02 AC 05
					39 00 00 00 00 00 04 FF 5A A5 08
					15 00 00 00 00 00 02 B0 55
					39 00 00 00 00 00 04 FF 5A A5 1C
					39 00 00 00 00 00 03 FD 00 94
					15 00 00 00 00 00 02 E1 A2
					39 00 00 00 00 00 03 FD 00 00
					39 00 00 00 00 00 04 FF 5A A5 08
					15 00 00 00 00 00 02 B0 00
					//page 00
					39 00 00 00 00 00 04 FF 5A A5 00
					15 00 00 00 78 00 02 11 00

					15 00 00 00 14 00 02 29 00
				];

				oplus,dsi-on-t0-command = [
					//OTP Don’t reload
					39 00 00 00 00 00 04 FF 5A A5 08
					15 00 00 00 00 00 02 C8 62

					39 00 00 00 00 00 04 FF 5A A5 07
					15 00 00 00 00 00 02 8A 01
					39 00 00 00 00 00 03 8B 21 E0
					39 00 00 00 00 00 64 81 00 00 00 00 00 12 00 00 ab 30 80 0a d4 04 f8 00 16 02 7c 02 7c 02 00 02 59 00 20 02 2e 00 08 00 0d 04 f4 03 ed 18 00 10 f0 07 10 20 00 06 0f 0f 33 0e 1c 2a 38 46 54 62 69 70 77 79 7b 7d 7e 02 02 22 00 2a 40 2a be 3a fc 3a fa 3a f8 3b 38 3b 78 3b b6 4b b6 4b f4 4b f4 6c 34 84 74 00 00 00 00 00 00
					//Ycrcb
					15 00 00 00 00 00 02 91 03
					//VINIT3 SKIP
					39 00 00 00 00 00 04 FF 5A A5 51
					39 00 00 00 00 00 06 A0 98 A9 A8 A8 22
					15 00 00 00 00 00 02 FE 22
					15 00 00 00 00 00 02 00 00
					39 00 00 00 00 00 06 A1 A8 A7 7A 74 22
					15 00 00 00 00 00 02 FE 22
					15 00 00 00 00 00 02 00 00
					39 00 00 00 00 00 06 A2 71 6A 6A 72 22
					15 00 00 00 00 00 02 FE 22
					15 00 00 00 00 00 02 00 00
					//VINIT2 SKIP
					39 00 00 00 00 00 04 FF 5A A5 52
					39 00 00 00 00 00 06 C0 7C D2 9E 47 01
					15 00 00 00 00 00 02 FE 00
					15 00 00 00 00 00 02 00 00
					39 00 00 00 00 00 06 C1 48 48 5C 64 00
					15 00 00 00 00 00 02 FE 00
					15 00 00 00 00 00 02 00 00
					39 00 00 00 00 00 06 C2 5E 52 50 53 00
					15 00 00 00 00 00 02 FE 00
					15 00 00 00 00 00 02 00 00
					//DDIC RCN config
					39 00 00 40 00 00 04 FF 5A A5 16
					39 00 00 40 00 00 05 80 38 00 2D 00
					39 00 00 40 00 00 05 81 A7 00 52 00
					39 00 00 40 00 00 05 82 2F 00 ED 00
					39 00 00 40 00 00 05 83 A9 00 87 00
					39 00 00 40 00 00 05 84 65 00 43 00
					39 00 00 40 00 00 05 85 32 00 10 00
					39 00 00 40 00 00 05 86 1F 00 FF 00
					39 00 00 40 00 00 05 87 EE 00 DE 00
					39 00 00 40 00 00 05 88 CD 00 CC 00
					39 00 00 40 00 00 05 89 BB 00 CA 00
					39 00 00 40 00 00 05 8A BA 00 AA 00
					39 00 00 40 00 00 05 8B A9 00 99 00
					39 00 00 40 00 00 05 8C 98 00 98 00
					39 00 00 40 00 00 05 8D 97 00 88 00
					39 00 00 40 00 00 05 8E 87 00 77 00
					39 00 00 40 00 00 05 8F 77 00 77 00
					39 00 00 40 00 00 05 90 66 00 76 00
					39 00 00 40 00 00 05 91 66 00 65 00
					39 00 00 40 00 00 05 92 66 00 56 00
					39 00 00 40 00 00 05 93 55 00 55 00
					39 00 00 40 00 00 05 94 55 00 45 00
					39 00 00 40 00 00 05 95 54 00 54 00
					39 00 00 40 00 00 05 96 54 00 44 00
					39 00 00 40 00 00 05 97 44 00 44 00
					39 00 00 40 00 00 05 98 43 00 44 00
					39 00 00 40 00 00 05 99 34 00 24 00
					39 00 00 40 00 00 05 9A 33 00 43 00
					39 00 00 40 00 00 05 9B 33 00 33 00
					39 00 00 40 00 00 05 9C 33 00 32 00
					39 00 00 40 00 00 05 9D 32 00 32 00
					39 00 00 40 00 00 05 9E 32 00 32 00
					39 00 00 40 00 00 05 9F 31 00 22 00
					39 00 00 40 00 00 05 A0 32 00 22 00
					39 00 00 40 00 00 05 A1 22 00 21 00
					39 00 00 40 00 00 05 A2 21 00 22 00
					39 00 00 40 00 00 05 A3 11 00 20 00
					39 00 00 40 00 00 05 A4 22 00 12 00
					39 00 00 40 00 00 05 A5 02 00 12 00
					39 00 00 40 00 00 05 A6 12 00 01 00
					39 00 00 40 00 00 05 A7 12 00 10 00
					39 00 00 40 00 00 05 A8 11 00 21 00
					39 00 00 40 00 00 05 A9 11 00 11 00
					39 00 00 40 00 00 05 AA 10 00 11 00
					39 00 00 40 00 00 05 AB 11 00 00 00
					39 00 00 40 00 00 05 AC 10 00 01 00
					39 00 00 40 00 00 05 AD 01 00 01 00
					39 00 00 40 00 00 05 AE 10 00 11 00
					39 00 00 40 00 00 05 AF 00 00 10 00
					39 00 00 40 00 00 05 B0 00 00 10 00
					39 00 00 40 00 00 05 B1 01 00 01 00
					39 00 00 40 00 00 05 B2 00 00 10 00
					39 00 00 40 00 00 05 B3 10 00 10 00
					39 00 00 40 00 00 05 B4 01 00 00 00
					39 00 00 40 00 00 05 B5 01 00 00 00
					39 00 00 40 00 00 05 B6 00 00 00 00
					39 00 00 40 00 00 05 B7 10 00 01 00
					39 00 00 40 00 00 05 B8 00 00 10 00
					39 00 00 40 00 00 05 B9 00 00 10 00
					39 00 00 40 00 00 05 BA 00 00 00 00
					39 00 00 40 00 00 05 BB 10 00 00 00
					39 00 00 40 00 00 05 BC 00 00 10 00
					39 00 00 40 00 00 05 BD 00 00 00 00
					39 00 00 40 00 00 05 BE 00 00 00 00
					39 00 00 40 00 00 04 FF 5A A5 17
					39 00 00 40 00 00 05 80 00 00 00 00
					39 00 00 40 00 00 05 81 00 00 00 00
					39 00 00 40 00 00 05 82 00 00 00 00
					39 00 00 40 00 00 05 83 00 00 00 00
					39 00 00 40 00 00 05 84 00 00 00 00
					39 00 00 40 00 00 05 85 00 00 00 00
					39 00 00 40 00 00 05 86 00 00 00 01
					39 00 00 40 00 00 05 87 01 01 01 10
					39 00 00 40 00 00 05 88 10 11 01 10
					39 00 00 40 00 00 05 89 01 10 11 11
					39 00 00 40 00 00 05 8A 11 01 11 12
					39 00 00 40 00 00 05 8B 11 01 11 12
					39 00 00 40 00 00 05 8C 11 21 12 12
					39 00 00 40 00 00 05 8D 12 12 11 21
					39 00 00 40 00 00 05 8E 22 22 21 22
					39 00 00 40 00 00 05 8F 22 32 22 22
					39 00 00 40 00 00 05 90 22 32 32 33
					39 00 00 40 00 00 05 91 23 32 33 32
					39 00 00 40 00 00 05 92 43 33 34 33
					39 00 00 40 00 00 05 93 43 44 34 34
					39 00 00 40 00 00 05 94 44 54 44 54
					39 00 00 40 00 00 05 95 45 54 55 55
					39 00 00 40 00 00 05 96 64 65 66 56
					39 00 00 40 00 00 05 97 66 66 76 76
					39 00 00 40 00 00 05 98 77 87 87 78
					39 00 00 40 00 00 05 99 97 98 99 99
					39 00 00 40 00 00 05 9A 9A AA AB BB
					39 00 00 40 00 00 05 9B BC CC DD DE
					39 00 00 40 00 00 05 9C EF E0 01 12
					39 00 00 40 00 00 05 9D 23 54 56 79
					39 00 00 40 00 00 05 9E AC E0 13 48
					39 00 00 40 00 00 05 9F C0 61 13 48
					15 00 00 40 00 00 02 A0 8E
					15 00 00 40 00 00 02 A1 D0
					15 00 00 40 00 00 02 A2 FB
					15 00 00 40 00 00 02 A3 FC
					15 00 00 40 00 00 02 A4 2F
					15 00 00 40 00 00 02 A5 FC
					39 00 00 40 00 00 10 A6 05 04 04 03 03 04 03 03 03 03 03 02 02 02 02
					15 00 00 40 00 00 02 A8 18
					15 00 00 40 00 00 02 A9 03
					15 00 00 40 00 00 02 AA 00
					15 00 00 40 00 00 02 AB 00
					15 00 00 40 00 00 02 AC 00
					15 00 00 40 00 00 02 AD 00
					15 00 00 40 00 00 02 AE 00
					39 00 00 40 00 00 07 EC 00 00 00 00 00 00
					15 00 00 40 00 00 02 AF 04
					15 00 00 40 00 00 02 B0 0A
					15 00 00 40 00 00 02 B1 1A
					15 00 00 40 00 00 02 B2 19
					15 00 00 40 00 00 02 B3 09
					15 00 00 40 00 00 02 B4 03
					39 00 00 40 00 00 07 EC 00 00 00 00 00 00
					15 00 00 40 00 00 02 C0 00
					15 00 00 40 00 00 02 C1 00
					15 00 00 40 00 00 02 C2 00
					15 00 00 40 00 00 02 C3 00
					15 00 00 40 00 00 02 C4 00
					15 00 00 40 00 00 02 C5 00
					15 00 00 40 00 00 02 C6 00
					15 00 00 40 00 00 02 C7 33
					15 00 00 40 00 00 02 CA 08
					15 00 00 40 00 00 02 CB 80
					15 00 00 40 00 00 02 CC 05
					15 00 00 40 00 00 02 CD 03
					15 00 00 40 00 00 02 CE 08
					15 00 00 40 00 00 02 CF 05
					15 00 00 40 00 00 02 D0 7F
					15 00 00 40 00 00 02 D1 2C
					15 00 00 40 00 00 02 D2 80
					15 00 00 40 00 00 02 D3 0D
					15 00 00 40 00 00 02 D4 07
					15 00 00 40 00 00 02 D5 0E
					15 00 00 40 00 00 02 D6 03
					15 00 00 40 00 00 02 D7 14
					15 00 00 40 00 00 02 D8 A0
					15 00 00 40 00 00 02 E7 21
					15 00 00 40 00 00 02 E8 20
					15 00 00 40 00 00 02 E9 30
					15 00 00 40 00 00 02 EA 03
					39 00 00 40 00 00 03 EF 00 00
					15 00 00 40 00 00 02 F1 70
					39 00 00 00 00 00 06 F8 05 00 80 00 00

					//CTB ON
					39 00 00 00 00 00 04 FF 5A A5 31
					15 00 00 00 00 00 02 A0 A3
					//CCTC ON
					39 00 00 00 00 00 04 FF 5A A5 07
					15 00 00 00 00 00 02 E5 05

					39 00 00 00 00 00 04 FF 5A A5 06
					//scramble disable
					15 00 00 00 00 00 02 A0 00
					//set para.num
					15 00 00 00 00 00 02 AB 03
					15 00 00 00 00 00 02 AE 12
					//Page 21
					39 00 00 00 00 00 04 FF 5A A5 21
					//flash reload enable
					15 00 00 00 00 00 02 A4 18
					//Page 0
					39 00 00 00 00 00 04 FF 5A A5 00
					//Skip frame Enable
					15 00 00 00 00 00 02 5E 01
					//Normal = 60Hz
					15 00 00 00 00 00 02 60 00
					39 00 00 00 00 00 04 FF 5A A5 2D
					39 00 00 00 00 00 03 83 01 00
					15 00 00 00 00 00 02 F2 01
					//Page 0
					39 00 00 00 00 00 04 FF 5A A5 00

					//AOD in = 30Hz
					15 00 00 00 00 00 02 61 07
					//TE On
					15 00 00 00 00 00 02 35 00
					//BC On, Dimming Off
					15 00 00 00 00 00 02 53 20
					//12-bit DBV,前两位输出normal的dbv，后两位为AOD的dbv
					39 00 00 00 00 00 05 51 00 00 07 FF
					39 00 00 00 00 00 04 FF 5A A5 20
					15 00 00 00 00 00 02 BC 07

					39 00 00 00 00 00 04 FF 5A A5 2F
					39 00 00 00 00 00 02 99 E4
					39 00 00 00 00 00 07 80 06 FE 08 72 0A 3C
					39 00 00 00 00 00 07 81 0D 90 0D A7 10 8C
					39 00 00 00 00 00 07 82 0D FC 0E 14 11 10
					39 00 00 00 00 00 07 83 0F 18 0E D0 12 24
					39 00 00 00 00 00 07 84 10 B8 0F E0 13 BC
					39 00 00 00 00 00 07 85 11 FC 10 F4 15 2C
					39 00 00 00 00 00 07 86 12 A8 11 94 15 FC
					39 00 00 00 00 00 07 87 13 F4 12 C4 17 8C
					39 00 00 00 00 00 07 88 14 F8 13 BC 18 C8
					39 00 00 00 00 00 07 89 16 78 15 28 1A 94
					39 00 00 00 00 00 07 8A 17 AC 16 50 1C 00
					39 00 00 00 00 00 07 8B 19 6C 17 FC 1E 14
					39 00 00 00 00 00 07 8C 1B 38 19 B0 20 38
					39 00 00 00 00 00 07 8D 1D 54 1B A4 22 A8
					39 00 00 00 00 00 07 8E 1F 30 1D 60 24 D0
					39 00 00 00 00 00 07 8F 20 70 1E 90 26 50
					39 00 00 00 00 00 07 90 21 CC 1F D0 27 F0
					39 00 00 00 00 00 07 91 23 50 21 34 29 C0
					39 00 00 00 00 00 07 92 25 4C 23 08 2C 2C
					39 00 00 00 00 00 07 93 27 44 24 CC 2E 8C
					39 00 00 00 00 00 07 94 28 30 25 9C 2F B4
					39 00 00 00 00 00 07 95 29 84 26 E0 31 74
					39 00 00 00 00 00 07 96 2B 0C 28 4C 33 78
					39 00 00 00 00 00 07 97 2D 78 2A 70 36 A0
					39 00 00 00 00 00 02 99 00
					//spr config
					39 00 00 40 00 00 04 FF 5A A5 14
					39 00 00 40 00 00 07 A3 00 04 00 04 70 80
					//LVD on
					39 00 00 00 00 00 04 FF 5A A5 05
					15 00 00 00 00 00 02 83 03
					15 00 00 00 00 00 02 84 03
					15 00 00 00 00 00 02 AA 94
					15 00 00 00 00 00 02 AB C9
					15 00 00 00 00 00 02 AC 05
					39 00 00 00 00 00 04 FF 5A A5 08
					15 00 00 00 00 00 02 B0 55
					39 00 00 00 00 00 04 FF 5A A5 1C
					39 00 00 00 00 00 03 FD 00 94
					15 00 00 00 00 00 02 E1 A2
					39 00 00 00 00 00 03 FD 00 00
					39 00 00 00 00 00 04 FF 5A A5 08
					15 00 00 00 00 00 02 B0 00
					//page 00
					39 00 00 00 00 00 04 FF 5A A5 00

					15 00 00 00 78 00 02 11 00
					15 00 00 00 14 00 02 29 00
				];

				oplus,dsi-aod-off-command = [
					39 00 00 40 00 00 04 FF 5A A5 08
					39 00 00 40 00 00 02 98 02
					39 00 00 40 00 00 04 FF 5A A5 4F
					39 00 00 40 00 00 02 81 06
					39 00 00 40 00 00 02 88 78
					39 00 00 40 00 00 04 FF 5A A5 05
					39 00 00 40 00 00 02 AE 94
					39 00 00 40 00 00 02 AF DF
					39 00 00 40 00 00 02 B1 9F
					39 00 00 40 00 00 02 B2 DF
					39 00 00 40 00 00 04 C2 2F 20 37
					39 00 00 40 00 00 03 C4 32 3E
					39 00 00 40 00 00 04 FF 5A A5 00
					39 00 00 40 00 00 02 38 00
					39 00 00 40 00 00 04 FF 5A A5 4F
					39 00 00 40 00 00 02 8A 78
					39 00 00 40 00 00 04 FF 5A A5 05
					39 00 00 40 00 00 02 AE 92
					39 00 00 40 00 00 02 AF DA
					39 00 00 40 00 00 02 B1 9B
					39 00 00 40 00 00 02 B2 DB
					39 00 00 40 00 00 04 C2 37 20 37
					39 00 00 40 00 00 03 C4 3E 3E
					39 00 00 40 00 00 04 FF 5A A5 08
					39 00 00 40 00 00 02 98 A6
					39 00 00 40 00 00 04 FF 5A A5 00
					39 00 00 40 00 00 02 00 00
					39 00 00 40 00 00 04 FF 5A A5 4F
					39 00 00 40 00 00 02 8B 78
					39 00 00 00 00 00 03 51 00 00
				];
				oplus,dsi-panel-aod-off-insert-black-command = [
					39 00 00 40 00 00 04 FF 5A A5 08
					39 00 00 40 00 00 02 98 02
					39 00 00 40 00 00 04 FF 5A A5 4F
					39 00 00 40 00 00 02 81 06
					39 00 00 40 00 00 02 88 78
					39 00 00 40 00 00 04 FF 5A A5 05
					39 00 00 40 00 00 02 AE 94
					39 00 00 40 00 00 02 AF DF
					39 00 00 40 00 00 02 B1 9F
					39 00 00 40 00 00 02 B2 DF
					39 00 00 40 00 00 04 C2 2F 20 37
					39 00 00 40 00 00 03 C4 32 3E
					39 00 00 40 00 00 04 FF 5A A5 00
					39 00 00 40 00 00 02 38 00
					39 00 00 40 00 00 04 FF 5A A5 4F
					39 00 00 40 00 00 02 8A 78
					39 00 00 40 00 00 04 FF 5A A5 05
					39 00 00 40 00 00 02 AE 92
					39 00 00 40 00 00 02 AF DA
					39 00 00 40 00 00 02 B1 9B
					39 00 00 40 00 00 02 B2 DB
					39 00 00 40 00 00 04 C2 37 20 37
					39 00 00 40 00 00 03 C4 3E 3E
					39 00 00 40 00 00 04 FF 5A A5 08
					39 00 00 40 00 00 02 98 A6
					39 00 00 40 00 00 04 FF 5A A5 00
					39 00 00 40 00 00 02 00 00
					39 00 00 40 00 00 04 FF 5A A5 4F
					39 00 00 40 00 00 02 8B 78
					39 00 00 00 00 00 03 51 00 00
				];
				oplus,dsi-lhbm-pressed-icon-on-command = [
					39 00 00 40 00 00 04 FF 5A A5 00
					39 00 00 40 00 00 02 6E 03
					39 00 00 40 00 00 02 96 09
					39 00 00 40 00 00 02 97 E3
					39 00 00 40 00 00 02 98 02
					39 00 00 40 00 00 02 99 7C
					39 00 00 00 00 00 07 2C 00 00 00 00 00 00
				];
				oplus,dsi-lhbm-pressed-icon-on-pwm-command = [

				];
				oplus,dsi-adfr-min-fps-60hz-command = [
					39 00 00 40 00 00 04 FF 5A A5 2D
					39 00 00 40 00 00 03 83 77 00
					15 00 00 40 00 00 02 97 03
					39 00 00 40 00 00 03 98 03 00
					39 00 00 40 00 00 03 99 0B 00
					39 00 00 40 00 00 03 9A 17 00
					39 00 00 40 00 00 03 9B 77 00
					39 00 00 40 00 00 05 A0 00 01 00 00
					39 00 00 40 00 00 05 A1 02 00 00 00
					39 00 00 40 00 00 03 83 01 00
					39 00 00 00 00 00 04 FF 5A A5 00
				];
				oplus,dsi-adfr-min-fps-30hz-command = [
					39 00 00 40 00 00 04 FF 5A A5 2D
					39 00 00 40 00 00 03 83 77 00
					15 00 00 40 00 00 02 97 03
					39 00 00 40 00 00 03 98 03 00
					39 00 00 40 00 00 03 99 0B 00
					39 00 00 40 00 00 03 9A 17 00
					39 00 00 40 00 00 03 9B 77 00
					39 00 00 40 00 00 05 A0 00 01 00 00
					39 00 00 40 00 00 05 A1 02 00 00 00
					39 00 00 40 00 00 03 83 03 00
					39 00 00 00 00 00 04 FF 5A A5 00
				];
				oplus,dsi-adfr-min-fps-20hz-command = [
				];
				oplus,dsi-adfr-min-fps-10hz-command = [
					39 00 00 40 00 00 04 FF 5A A5 2D
					39 00 00 40 00 00 03 83 77 00
					15 00 00 40 00 00 02 97 03
					39 00 00 40 00 00 03 98 03 00
					39 00 00 40 00 00 03 99 0B 00
					39 00 00 40 00 00 03 9A 17 00
					39 00 00 40 00 00 03 9B 77 00
					39 00 00 40 00 00 05 A0 00 01 00 00
					39 00 00 40 00 00 05 A1 02 00 00 00
					39 00 00 40 00 00 03 83 0B 00
					39 00 00 00 00 00 04 FF 5A A5 00
				];
				oplus,dsi-adfr-min-fps-5hz-command = [
				];
				oplus,dsi-adfr-min-fps-1hz-command = [
					39 00 00 40 00 00 04 FF 5A A5 2D
					39 00 00 40 00 00 03 83 77 00
					15 00 00 40 00 00 02 97 03
					39 00 00 40 00 00 03 98 03 00
					39 00 00 40 00 00 03 99 0B 00
					39 00 00 40 00 00 03 9A 17 00
					39 00 00 40 00 00 03 9B 77 00
					39 00 00 40 00 00 05 A0 00 01 00 00
					39 00 00 40 00 00 05 A1 02 00 00 00
					39 00 00 40 00 00 03 83 77 00
					39 00 00 00 00 00 04 FF 5A A5 00
				];

				oplus,dsi-timing-switch-command-state = "dsi_hs_mode";
				oplus,dsi-pwm-switch-1to3pul-command-state = "dsi_hs_mode";
				oplus,dsi-pwm-switch-1to18pul-command-state = "dsi_hs_mode";
				oplus,dsi-pwm-switch-18to3pul-command-state = "dsi_hs_mode";
				oplus,dsi-pwm-switch-3to18pul-command-state = "dsi_hs_mode";
				oplus,dsi-timing-switch-1pulse-command-state = "dsi_hs_mode";
				oplus,dsi-pwm-switch-3to1pul-command-state = "dsi_hs_mode";
				oplus,dsi-pwm-switch-18to1pul-command-state = "dsi_hs_mode";
				oplus,dsi-on-command-state = "dsi_lp_mode";
				oplus,dsi-on-t0-command-state = "dsi_lp_mode";
				oplus,dsi-aod-off-command-state = "dsi_ls_mode";
				oplus,dsi-panel-aod-off-insert-black-command-state = "dsi_ls_mode";
				oplus,dsi-lhbm-pressed-icon-on-command-state = "dsi_hs_mode";
				oplus,dsi-lhbm-pressed-icon-on-pwm-command-state = "dsi_hs_mode";
				oplus,dsi-adfr-min-fps-60hz-command-state = "dsi_hs_mode";
				oplus,dsi-adfr-min-fps-30hz-command-state = "dsi_hs_mode";
				oplus,dsi-adfr-min-fps-20hz-command-state = "dsi_hs_mode";
				oplus,dsi-adfr-min-fps-10hz-command-state = "dsi_hs_mode";
				oplus,dsi-adfr-min-fps-5hz-command-state = "dsi_hs_mode";
				oplus,dsi-adfr-min-fps-1hz-command-state = "dsi_hs_mode";

				oplus,dsc-params-entries = <&dsc_params>;
/*				oplus,phy-timcon {
					hs-trail = <14>;
					clk-trail = <15>;
				};*/
				oplus,dyn-fps {
					switch_en = <1>;
					vact_timing_fps = <60>;
					apollo_limit_superior_us = <10000>;
					apollo_limit_inferior_us = <13596>;
					apollo_transfer_time_us = <8200>;
				};
				oplus,display-mode {
					display-mode@0 {
						hdisplay = <1272>;
						vdisplay = <2772>;
/*						fhd-hfp = <9>;
						fhd-hsa = <2>;
						fhd-hbp = <21>;
						fhd-vfp = <52>;
						fhd-vsa = <14>;
						fhd-vbp = <22>;*/
						hskew = <STANDARD_ADFR>;
					};
					display-mode@1 {
						hdisplay = <1080>;
						vdisplay = <2354>;
/*						fhd-hfp = <9>;
						fhd-hsa = <2>;
						fhd-hbp = <21>;
						fhd-vfp = <52>;
						fhd-vsa = <14>;
						fhd-vbp = <22>;*/
						hskew = <STANDARD_ADFR>;
					};
				};
			};
			timing@oa_fhd_120 {
				cell-index = <3>;
				oplus,dsi-panel-framerate = <120>;
				oplus,adfr-timing-type = <2>;
				oplus,dsi-panel-pllclk = <553>;
				oplus,merge-trig-offset = <333>;
				//oplus,cmd-null-pkt-en = <1>;
				//oplus,cmd-null-pkt-len = <0>;
				/* OPLUS_FEATURE_DISPLAY_ONSCREENFINGERPRINT */
				oplus,ofp_need_keep_apart_backlight;
				oplus,ofp-hbm-on-delay = <0>;
				oplus,ofp-pre-hbm-off-delay = <2>;
				oplus,ofp-hbm-off-delay = <0>;
				oplus,ofp-need-to-sync-data-in-aod-unlocking;
				oplus,ofp-aod-off-insert-black = <1>;
				oplus,ofp-aod-off-black-frame-total-time = <42>;
				#include "ac330-p-3-a0020-dsi-cmd-panel-common.dtsi"
				oplus,dsi-timing-switch-command = [//Switch To 120Hz normal
					39 00 00 40 00 00 04 FF 5A A5 00
					15 00 00 40 00 00 02 60 00
					15 00 00 40 00 00 02 7D 00
					39 00 00 40 00 00 04 FF 5A A5 2D
					39 00 00 40 00 00 03 83 00 00
					15 00 00 40 00 00 02 F2 00
					39 00 00 00 00 00 04 FF 5A A5 00
				];
				oplus,dsi-pwm-switch-1to3pul-command = [
				];
				oplus,dsi-pwm-switch-1to18pul-command = [
				];
				oplus,dsi-pwm-switch-18to3pul-command = [
				];
				oplus,dsi-pwm-switch-3to18pul-command = [
				];
				oplus,dsi-timing-switch-1pulse-command = [
				];
				oplus,dsi-pwm-switch-3to1pul-command = [
				];
				oplus,dsi-pwm-switch-18to1pul-command = [
				];
				oplus,dsi-on-command = [
					//OTP Don’t reload
					39 00 00 00 00 00 04 FF 5A A5 08
					15 00 00 00 00 00 02 C8 62

					39 00 00 00 00 00 04 FF 5A A5 07
					15 00 00 00 00 00 02 8A 01
					39 00 00 00 00 00 03 8B 21 E0
					39 00 00 00 00 00 64 81 00 00 00 00 00 12 00 00 ab 30 80 0a d4 04 f8 00 16 02 7c 02 7c 02 00 02 59 00 20 02 2e 00 08 00 0d 04 f4 03 ed 18 00 10 f0 07 10 20 00 06 0f 0f 33 0e 1c 2a 38 46 54 62 69 70 77 79 7b 7d 7e 02 02 22 00 2a 40 2a be 3a fc 3a fa 3a f8 3b 38 3b 78 3b b6 4b b6 4b f4 4b f4 6c 34 84 74 00 00 00 00 00 00
					//Ycrcb
					15 00 00 00 00 00 02 91 03
					//VINIT3 SKIP
					39 00 00 00 00 00 04 FF 5A A5 51
					39 00 00 00 00 00 06 A0 98 A9 A8 A8 22
					15 00 00 00 00 00 02 FE 22
					15 00 00 00 00 00 02 00 00
					39 00 00 00 00 00 06 A1 A8 A7 7A 74 22
					15 00 00 00 00 00 02 FE 22
					15 00 00 00 00 00 02 00 00
					39 00 00 00 00 00 06 A2 71 6A 6A 72 22
					15 00 00 00 00 00 02 FE 22
					15 00 00 00 00 00 02 00 00
					//VINIT2 SKIP
					39 00 00 00 00 00 04 FF 5A A5 52
					39 00 00 00 00 00 06 C0 7C D2 9E 47 01
					15 00 00 00 00 00 02 FE 00
					15 00 00 00 00 00 02 00 00
					39 00 00 00 00 00 06 C1 48 48 5C 64 00
					15 00 00 00 00 00 02 FE 00
					15 00 00 00 00 00 02 00 00
					39 00 00 00 00 00 06 C2 5E 52 50 53 00
					15 00 00 00 00 00 02 FE 00
					15 00 00 00 00 00 02 00 00
					//DDIC RCN config
					39 00 00 40 00 00 04 FF 5A A5 16
					39 00 00 40 00 00 05 80 38 00 2D 00
					39 00 00 40 00 00 05 81 A7 00 52 00
					39 00 00 40 00 00 05 82 2F 00 ED 00
					39 00 00 40 00 00 05 83 A9 00 87 00
					39 00 00 40 00 00 05 84 65 00 43 00
					39 00 00 40 00 00 05 85 32 00 10 00
					39 00 00 40 00 00 05 86 1F 00 FF 00
					39 00 00 40 00 00 05 87 EE 00 DE 00
					39 00 00 40 00 00 05 88 CD 00 CC 00
					39 00 00 40 00 00 05 89 BB 00 CA 00
					39 00 00 40 00 00 05 8A BA 00 AA 00
					39 00 00 40 00 00 05 8B A9 00 99 00
					39 00 00 40 00 00 05 8C 98 00 98 00
					39 00 00 40 00 00 05 8D 97 00 88 00
					39 00 00 40 00 00 05 8E 87 00 77 00
					39 00 00 40 00 00 05 8F 77 00 77 00
					39 00 00 40 00 00 05 90 66 00 76 00
					39 00 00 40 00 00 05 91 66 00 65 00
					39 00 00 40 00 00 05 92 66 00 56 00
					39 00 00 40 00 00 05 93 55 00 55 00
					39 00 00 40 00 00 05 94 55 00 45 00
					39 00 00 40 00 00 05 95 54 00 54 00
					39 00 00 40 00 00 05 96 54 00 44 00
					39 00 00 40 00 00 05 97 44 00 44 00
					39 00 00 40 00 00 05 98 43 00 44 00
					39 00 00 40 00 00 05 99 34 00 24 00
					39 00 00 40 00 00 05 9A 33 00 43 00
					39 00 00 40 00 00 05 9B 33 00 33 00
					39 00 00 40 00 00 05 9C 33 00 32 00
					39 00 00 40 00 00 05 9D 32 00 32 00
					39 00 00 40 00 00 05 9E 32 00 32 00
					39 00 00 40 00 00 05 9F 31 00 22 00
					39 00 00 40 00 00 05 A0 32 00 22 00
					39 00 00 40 00 00 05 A1 22 00 21 00
					39 00 00 40 00 00 05 A2 21 00 22 00
					39 00 00 40 00 00 05 A3 11 00 20 00
					39 00 00 40 00 00 05 A4 22 00 12 00
					39 00 00 40 00 00 05 A5 02 00 12 00
					39 00 00 40 00 00 05 A6 12 00 01 00
					39 00 00 40 00 00 05 A7 12 00 10 00
					39 00 00 40 00 00 05 A8 11 00 21 00
					39 00 00 40 00 00 05 A9 11 00 11 00
					39 00 00 40 00 00 05 AA 10 00 11 00
					39 00 00 40 00 00 05 AB 11 00 00 00
					39 00 00 40 00 00 05 AC 10 00 01 00
					39 00 00 40 00 00 05 AD 01 00 01 00
					39 00 00 40 00 00 05 AE 10 00 11 00
					39 00 00 40 00 00 05 AF 00 00 10 00
					39 00 00 40 00 00 05 B0 00 00 10 00
					39 00 00 40 00 00 05 B1 01 00 01 00
					39 00 00 40 00 00 05 B2 00 00 10 00
					39 00 00 40 00 00 05 B3 10 00 10 00
					39 00 00 40 00 00 05 B4 01 00 00 00
					39 00 00 40 00 00 05 B5 01 00 00 00
					39 00 00 40 00 00 05 B6 00 00 00 00
					39 00 00 40 00 00 05 B7 10 00 01 00
					39 00 00 40 00 00 05 B8 00 00 10 00
					39 00 00 40 00 00 05 B9 00 00 10 00
					39 00 00 40 00 00 05 BA 00 00 00 00
					39 00 00 40 00 00 05 BB 10 00 00 00
					39 00 00 40 00 00 05 BC 00 00 10 00
					39 00 00 40 00 00 05 BD 00 00 00 00
					39 00 00 40 00 00 05 BE 00 00 00 00
					39 00 00 40 00 00 04 FF 5A A5 17
					39 00 00 40 00 00 05 80 00 00 00 00
					39 00 00 40 00 00 05 81 00 00 00 00
					39 00 00 40 00 00 05 82 00 00 00 00
					39 00 00 40 00 00 05 83 00 00 00 00
					39 00 00 40 00 00 05 84 00 00 00 00
					39 00 00 40 00 00 05 85 00 00 00 00
					39 00 00 40 00 00 05 86 00 00 00 01
					39 00 00 40 00 00 05 87 01 01 01 10
					39 00 00 40 00 00 05 88 10 11 01 10
					39 00 00 40 00 00 05 89 01 10 11 11
					39 00 00 40 00 00 05 8A 11 01 11 12
					39 00 00 40 00 00 05 8B 11 01 11 12
					39 00 00 40 00 00 05 8C 11 21 12 12
					39 00 00 40 00 00 05 8D 12 12 11 21
					39 00 00 40 00 00 05 8E 22 22 21 22
					39 00 00 40 00 00 05 8F 22 32 22 22
					39 00 00 40 00 00 05 90 22 32 32 33
					39 00 00 40 00 00 05 91 23 32 33 32
					39 00 00 40 00 00 05 92 43 33 34 33
					39 00 00 40 00 00 05 93 43 44 34 34
					39 00 00 40 00 00 05 94 44 54 44 54
					39 00 00 40 00 00 05 95 45 54 55 55
					39 00 00 40 00 00 05 96 64 65 66 56
					39 00 00 40 00 00 05 97 66 66 76 76
					39 00 00 40 00 00 05 98 77 87 87 78
					39 00 00 40 00 00 05 99 97 98 99 99
					39 00 00 40 00 00 05 9A 9A AA AB BB
					39 00 00 40 00 00 05 9B BC CC DD DE
					39 00 00 40 00 00 05 9C EF E0 01 12
					39 00 00 40 00 00 05 9D 23 54 56 79
					39 00 00 40 00 00 05 9E AC E0 13 48
					39 00 00 40 00 00 05 9F C0 61 13 48
					15 00 00 40 00 00 02 A0 8E
					15 00 00 40 00 00 02 A1 D0
					15 00 00 40 00 00 02 A2 FB
					15 00 00 40 00 00 02 A3 FC
					15 00 00 40 00 00 02 A4 2F
					15 00 00 40 00 00 02 A5 FC
					39 00 00 40 00 00 10 A6 05 04 04 03 03 04 03 03 03 03 03 02 02 02 02
					15 00 00 40 00 00 02 A8 18
					15 00 00 40 00 00 02 A9 03
					15 00 00 40 00 00 02 AA 00
					15 00 00 40 00 00 02 AB 00
					15 00 00 40 00 00 02 AC 00
					15 00 00 40 00 00 02 AD 00
					15 00 00 40 00 00 02 AE 00
					39 00 00 40 00 00 07 EC 00 00 00 00 00 00
					15 00 00 40 00 00 02 AF 04
					15 00 00 40 00 00 02 B0 0A
					15 00 00 40 00 00 02 B1 1A
					15 00 00 40 00 00 02 B2 19
					15 00 00 40 00 00 02 B3 09
					15 00 00 40 00 00 02 B4 03
					39 00 00 40 00 00 07 EC 00 00 00 00 00 00
					15 00 00 40 00 00 02 C0 00
					15 00 00 40 00 00 02 C1 00
					15 00 00 40 00 00 02 C2 00
					15 00 00 40 00 00 02 C3 00
					15 00 00 40 00 00 02 C4 00
					15 00 00 40 00 00 02 C5 00
					15 00 00 40 00 00 02 C6 00
					15 00 00 40 00 00 02 C7 33
					15 00 00 40 00 00 02 CA 08
					15 00 00 40 00 00 02 CB 80
					15 00 00 40 00 00 02 CC 05
					15 00 00 40 00 00 02 CD 03
					15 00 00 40 00 00 02 CE 08
					15 00 00 40 00 00 02 CF 05
					15 00 00 40 00 00 02 D0 7F
					15 00 00 40 00 00 02 D1 2C
					15 00 00 40 00 00 02 D2 80
					15 00 00 40 00 00 02 D3 0D
					15 00 00 40 00 00 02 D4 07
					15 00 00 40 00 00 02 D5 0E
					15 00 00 40 00 00 02 D6 03
					15 00 00 40 00 00 02 D7 14
					15 00 00 40 00 00 02 D8 A0
					15 00 00 40 00 00 02 E7 21
					15 00 00 40 00 00 02 E8 20
					15 00 00 40 00 00 02 E9 30
					15 00 00 40 00 00 02 EA 03
					39 00 00 40 00 00 03 EF 00 00
					15 00 00 40 00 00 02 F1 70
					39 00 00 00 00 00 06 F8 05 00 80 00 00

					//CTB ON
					39 00 00 00 00 00 04 FF 5A A5 31
					15 00 00 00 00 00 02 A0 A3
					//CCTC ON
					39 00 00 00 00 00 04 FF 5A A5 07
					15 00 00 00 00 00 02 E5 05

					39 00 00 00 00 00 04 FF 5A A5 06
					//scramble disable
					15 00 00 00 00 00 02 A0 00
					//set para.num
					15 00 00 00 00 00 02 AB 03
					15 00 00 00 00 00 02 AE 12
					//Page 21
					39 00 00 00 00 00 04 FF 5A A5 21
					//flash reload enable
					15 00 00 00 00 00 02 A4 18
					//Page 0
					39 00 00 00 00 00 04 FF 5A A5 00
					//Skip frame Enable
					15 00 00 00 00 00 02 5E 01
					//Normal = 120Hz
					15 00 00 00 00 00 02 60 00
					//AOD in = 30Hz
					15 00 00 00 00 00 02 61 07
					//TE On
					15 00 00 00 00 00 02 35 00
					//BC On, Dimming Off
					15 00 00 00 00 00 02 53 20
					//12-bit DBV,前两位输出normal的dbv，后两位为AOD的dbv
					39 00 00 00 00 00 05 51 00 00 07 FF
					39 00 00 00 00 00 04 FF 5A A5 20
					15 00 00 00 00 00 02 BC 07
					39 00 00 40 00 00 04 FF 5A A5 2D
					39 00 00 40 00 00 03 83 77 00
					15 00 00 40 00 00 02 97 03
					39 00 00 40 00 00 03 98 03 00
					39 00 00 40 00 00 03 99 0B 00
					39 00 00 40 00 00 03 9A 17 00
					39 00 00 40 00 00 03 9B 77 00
					39 00 00 40 00 00 05 A0 00 01 00 00
					39 00 00 40 00 00 05 A1 02 00 00 00
					39 00 00 40 00 00 03 83 00 00
					//spr config
					39 00 00 40 00 00 04 FF 5A A5 14
					39 00 00 40 00 00 07 A3 00 04 00 04 70 80
					//LVD on
					39 00 00 00 00 00 04 FF 5A A5 05
					15 00 00 00 00 00 02 83 03
					15 00 00 00 00 00 02 84 03
					15 00 00 00 00 00 02 AA 94
					15 00 00 00 00 00 02 AB C9
					15 00 00 00 00 00 02 AC 05
					39 00 00 00 00 00 04 FF 5A A5 08
					15 00 00 00 00 00 02 B0 55
					39 00 00 00 00 00 04 FF 5A A5 1C
					39 00 00 00 00 00 03 FD 00 94
					15 00 00 00 00 00 02 E1 A2
					39 00 00 00 00 00 03 FD 00 00
					39 00 00 00 00 00 04 FF 5A A5 08
					15 00 00 00 00 00 02 B0 00
					//page 00
					39 00 00 00 00 00 04 FF 5A A5 00
					15 00 00 00 78 00 02 11 00

					15 00 00 00 14 00 02 29 00
				];

				oplus,dsi-on-t0-command = [
					//OTP Don’t reload
					39 00 00 00 00 00 04 FF 5A A5 08
					15 00 00 00 00 00 02 C8 62

					39 00 00 00 00 00 04 FF 5A A5 07
					15 00 00 00 00 00 02 8A 01
					39 00 00 00 00 00 03 8B 21 E0
					39 00 00 00 00 00 64 81 00 00 00 00 00 12 00 00 ab 30 80 0a d4 04 f8 00 16 02 7c 02 7c 02 00 02 59 00 20 02 2e 00 08 00 0d 04 f4 03 ed 18 00 10 f0 07 10 20 00 06 0f 0f 33 0e 1c 2a 38 46 54 62 69 70 77 79 7b 7d 7e 02 02 22 00 2a 40 2a be 3a fc 3a fa 3a f8 3b 38 3b 78 3b b6 4b b6 4b f4 4b f4 6c 34 84 74 00 00 00 00 00 00
					//Ycrcb
					15 00 00 00 00 00 02 91 03
					//VINIT3 SKIP
					39 00 00 00 00 00 04 FF 5A A5 51
					39 00 00 00 00 00 06 A0 98 A9 A8 A8 22
					15 00 00 00 00 00 02 FE 22
					15 00 00 00 00 00 02 00 00
					39 00 00 00 00 00 06 A1 A8 A7 7A 74 22
					15 00 00 00 00 00 02 FE 22
					15 00 00 00 00 00 02 00 00
					39 00 00 00 00 00 06 A2 71 6A 6A 72 22
					15 00 00 00 00 00 02 FE 22
					15 00 00 00 00 00 02 00 00
					//VINIT2 SKIP
					39 00 00 00 00 00 04 FF 5A A5 52
					39 00 00 00 00 00 06 C0 7C D2 9E 47 01
					15 00 00 00 00 00 02 FE 00
					15 00 00 00 00 00 02 00 00
					39 00 00 00 00 00 06 C1 48 48 5C 64 00
					15 00 00 00 00 00 02 FE 00
					15 00 00 00 00 00 02 00 00
					39 00 00 00 00 00 06 C2 5E 52 50 53 00
					15 00 00 00 00 00 02 FE 00
					15 00 00 00 00 00 02 00 00
					//DDIC RCN config
					39 00 00 40 00 00 04 FF 5A A5 16
					39 00 00 40 00 00 05 80 38 00 2D 00
					39 00 00 40 00 00 05 81 A7 00 52 00
					39 00 00 40 00 00 05 82 2F 00 ED 00
					39 00 00 40 00 00 05 83 A9 00 87 00
					39 00 00 40 00 00 05 84 65 00 43 00
					39 00 00 40 00 00 05 85 32 00 10 00
					39 00 00 40 00 00 05 86 1F 00 FF 00
					39 00 00 40 00 00 05 87 EE 00 DE 00
					39 00 00 40 00 00 05 88 CD 00 CC 00
					39 00 00 40 00 00 05 89 BB 00 CA 00
					39 00 00 40 00 00 05 8A BA 00 AA 00
					39 00 00 40 00 00 05 8B A9 00 99 00
					39 00 00 40 00 00 05 8C 98 00 98 00
					39 00 00 40 00 00 05 8D 97 00 88 00
					39 00 00 40 00 00 05 8E 87 00 77 00
					39 00 00 40 00 00 05 8F 77 00 77 00
					39 00 00 40 00 00 05 90 66 00 76 00
					39 00 00 40 00 00 05 91 66 00 65 00
					39 00 00 40 00 00 05 92 66 00 56 00
					39 00 00 40 00 00 05 93 55 00 55 00
					39 00 00 40 00 00 05 94 55 00 45 00
					39 00 00 40 00 00 05 95 54 00 54 00
					39 00 00 40 00 00 05 96 54 00 44 00
					39 00 00 40 00 00 05 97 44 00 44 00
					39 00 00 40 00 00 05 98 43 00 44 00
					39 00 00 40 00 00 05 99 34 00 24 00
					39 00 00 40 00 00 05 9A 33 00 43 00
					39 00 00 40 00 00 05 9B 33 00 33 00
					39 00 00 40 00 00 05 9C 33 00 32 00
					39 00 00 40 00 00 05 9D 32 00 32 00
					39 00 00 40 00 00 05 9E 32 00 32 00
					39 00 00 40 00 00 05 9F 31 00 22 00
					39 00 00 40 00 00 05 A0 32 00 22 00
					39 00 00 40 00 00 05 A1 22 00 21 00
					39 00 00 40 00 00 05 A2 21 00 22 00
					39 00 00 40 00 00 05 A3 11 00 20 00
					39 00 00 40 00 00 05 A4 22 00 12 00
					39 00 00 40 00 00 05 A5 02 00 12 00
					39 00 00 40 00 00 05 A6 12 00 01 00
					39 00 00 40 00 00 05 A7 12 00 10 00
					39 00 00 40 00 00 05 A8 11 00 21 00
					39 00 00 40 00 00 05 A9 11 00 11 00
					39 00 00 40 00 00 05 AA 10 00 11 00
					39 00 00 40 00 00 05 AB 11 00 00 00
					39 00 00 40 00 00 05 AC 10 00 01 00
					39 00 00 40 00 00 05 AD 01 00 01 00
					39 00 00 40 00 00 05 AE 10 00 11 00
					39 00 00 40 00 00 05 AF 00 00 10 00
					39 00 00 40 00 00 05 B0 00 00 10 00
					39 00 00 40 00 00 05 B1 01 00 01 00
					39 00 00 40 00 00 05 B2 00 00 10 00
					39 00 00 40 00 00 05 B3 10 00 10 00
					39 00 00 40 00 00 05 B4 01 00 00 00
					39 00 00 40 00 00 05 B5 01 00 00 00
					39 00 00 40 00 00 05 B6 00 00 00 00
					39 00 00 40 00 00 05 B7 10 00 01 00
					39 00 00 40 00 00 05 B8 00 00 10 00
					39 00 00 40 00 00 05 B9 00 00 10 00
					39 00 00 40 00 00 05 BA 00 00 00 00
					39 00 00 40 00 00 05 BB 10 00 00 00
					39 00 00 40 00 00 05 BC 00 00 10 00
					39 00 00 40 00 00 05 BD 00 00 00 00
					39 00 00 40 00 00 05 BE 00 00 00 00
					39 00 00 40 00 00 04 FF 5A A5 17
					39 00 00 40 00 00 05 80 00 00 00 00
					39 00 00 40 00 00 05 81 00 00 00 00
					39 00 00 40 00 00 05 82 00 00 00 00
					39 00 00 40 00 00 05 83 00 00 00 00
					39 00 00 40 00 00 05 84 00 00 00 00
					39 00 00 40 00 00 05 85 00 00 00 00
					39 00 00 40 00 00 05 86 00 00 00 01
					39 00 00 40 00 00 05 87 01 01 01 10
					39 00 00 40 00 00 05 88 10 11 01 10
					39 00 00 40 00 00 05 89 01 10 11 11
					39 00 00 40 00 00 05 8A 11 01 11 12
					39 00 00 40 00 00 05 8B 11 01 11 12
					39 00 00 40 00 00 05 8C 11 21 12 12
					39 00 00 40 00 00 05 8D 12 12 11 21
					39 00 00 40 00 00 05 8E 22 22 21 22
					39 00 00 40 00 00 05 8F 22 32 22 22
					39 00 00 40 00 00 05 90 22 32 32 33
					39 00 00 40 00 00 05 91 23 32 33 32
					39 00 00 40 00 00 05 92 43 33 34 33
					39 00 00 40 00 00 05 93 43 44 34 34
					39 00 00 40 00 00 05 94 44 54 44 54
					39 00 00 40 00 00 05 95 45 54 55 55
					39 00 00 40 00 00 05 96 64 65 66 56
					39 00 00 40 00 00 05 97 66 66 76 76
					39 00 00 40 00 00 05 98 77 87 87 78
					39 00 00 40 00 00 05 99 97 98 99 99
					39 00 00 40 00 00 05 9A 9A AA AB BB
					39 00 00 40 00 00 05 9B BC CC DD DE
					39 00 00 40 00 00 05 9C EF E0 01 12
					39 00 00 40 00 00 05 9D 23 54 56 79
					39 00 00 40 00 00 05 9E AC E0 13 48
					39 00 00 40 00 00 05 9F C0 61 13 48
					15 00 00 40 00 00 02 A0 8E
					15 00 00 40 00 00 02 A1 D0
					15 00 00 40 00 00 02 A2 FB
					15 00 00 40 00 00 02 A3 FC
					15 00 00 40 00 00 02 A4 2F
					15 00 00 40 00 00 02 A5 FC
					39 00 00 40 00 00 10 A6 05 04 04 03 03 04 03 03 03 03 03 02 02 02 02
					15 00 00 40 00 00 02 A8 18
					15 00 00 40 00 00 02 A9 03
					15 00 00 40 00 00 02 AA 00
					15 00 00 40 00 00 02 AB 00
					15 00 00 40 00 00 02 AC 00
					15 00 00 40 00 00 02 AD 00
					15 00 00 40 00 00 02 AE 00
					39 00 00 40 00 00 07 EC 00 00 00 00 00 00
					15 00 00 40 00 00 02 AF 04
					15 00 00 40 00 00 02 B0 0A
					15 00 00 40 00 00 02 B1 1A
					15 00 00 40 00 00 02 B2 19
					15 00 00 40 00 00 02 B3 09
					15 00 00 40 00 00 02 B4 03
					39 00 00 40 00 00 07 EC 00 00 00 00 00 00
					15 00 00 40 00 00 02 C0 00
					15 00 00 40 00 00 02 C1 00
					15 00 00 40 00 00 02 C2 00
					15 00 00 40 00 00 02 C3 00
					15 00 00 40 00 00 02 C4 00
					15 00 00 40 00 00 02 C5 00
					15 00 00 40 00 00 02 C6 00
					15 00 00 40 00 00 02 C7 33
					15 00 00 40 00 00 02 CA 08
					15 00 00 40 00 00 02 CB 80
					15 00 00 40 00 00 02 CC 05
					15 00 00 40 00 00 02 CD 03
					15 00 00 40 00 00 02 CE 08
					15 00 00 40 00 00 02 CF 05
					15 00 00 40 00 00 02 D0 7F
					15 00 00 40 00 00 02 D1 2C
					15 00 00 40 00 00 02 D2 80
					15 00 00 40 00 00 02 D3 0D
					15 00 00 40 00 00 02 D4 07
					15 00 00 40 00 00 02 D5 0E
					15 00 00 40 00 00 02 D6 03
					15 00 00 40 00 00 02 D7 14
					15 00 00 40 00 00 02 D8 A0
					15 00 00 40 00 00 02 E7 21
					15 00 00 40 00 00 02 E8 20
					15 00 00 40 00 00 02 E9 30
					15 00 00 40 00 00 02 EA 03
					39 00 00 40 00 00 03 EF 00 00
					15 00 00 40 00 00 02 F1 70
					39 00 00 00 00 00 06 F8 05 00 80 00 00

					//CTB ON
					39 00 00 00 00 00 04 FF 5A A5 31
					15 00 00 00 00 00 02 A0 A3
					//CCTC ON
					39 00 00 00 00 00 04 FF 5A A5 07
					15 00 00 00 00 00 02 E5 05

					39 00 00 00 00 00 04 FF 5A A5 06
					//scramble disable
					15 00 00 00 00 00 02 A0 00
					//set para.num
					15 00 00 00 00 00 02 AB 03
					15 00 00 00 00 00 02 AE 12
					//Page 21
					39 00 00 00 00 00 04 FF 5A A5 21
					//flash reload enable
					15 00 00 00 00 00 02 A4 18
					//Page 0
					39 00 00 00 00 00 04 FF 5A A5 00
					//Skip frame Enable
					15 00 00 00 00 00 02 5E 01
					//Normal = 120Hz
					15 00 00 00 00 00 02 60 00
					//AOD in = 30Hz
					15 00 00 00 00 00 02 61 07
					//TE On
					15 00 00 00 00 00 02 35 00
					//BC On, Dimming Off
					15 00 00 00 00 00 02 53 20
					//12-bit DBV,前两位输出normal的dbv，后两位为AOD的dbv
					39 00 00 00 00 00 05 51 00 00 07 FF
					39 00 00 00 00 00 04 FF 5A A5 20
					15 00 00 00 00 00 02 BC 07

					39 00 00 00 00 00 04 FF 5A A5 2F
					39 00 00 00 00 00 02 99 E4
					39 00 00 00 00 00 07 80 06 FE 08 72 0A 3C
					39 00 00 00 00 00 07 81 0D 90 0D A7 10 8C
					39 00 00 00 00 00 07 82 0D FC 0E 14 11 10
					39 00 00 00 00 00 07 83 0F 18 0E D0 12 24
					39 00 00 00 00 00 07 84 10 B8 0F E0 13 BC
					39 00 00 00 00 00 07 85 11 FC 10 F4 15 2C
					39 00 00 00 00 00 07 86 12 A8 11 94 15 FC
					39 00 00 00 00 00 07 87 13 F4 12 C4 17 8C
					39 00 00 00 00 00 07 88 14 F8 13 BC 18 C8
					39 00 00 00 00 00 07 89 16 78 15 28 1A 94
					39 00 00 00 00 00 07 8A 17 AC 16 50 1C 00
					39 00 00 00 00 00 07 8B 19 6C 17 FC 1E 14
					39 00 00 00 00 00 07 8C 1B 38 19 B0 20 38
					39 00 00 00 00 00 07 8D 1D 54 1B A4 22 A8
					39 00 00 00 00 00 07 8E 1F 30 1D 60 24 D0
					39 00 00 00 00 00 07 8F 20 70 1E 90 26 50
					39 00 00 00 00 00 07 90 21 CC 1F D0 27 F0
					39 00 00 00 00 00 07 91 23 50 21 34 29 C0
					39 00 00 00 00 00 07 92 25 4C 23 08 2C 2C
					39 00 00 00 00 00 07 93 27 44 24 CC 2E 8C
					39 00 00 00 00 00 07 94 28 30 25 9C 2F B4
					39 00 00 00 00 00 07 95 29 84 26 E0 31 74
					39 00 00 00 00 00 07 96 2B 0C 28 4C 33 78
					39 00 00 00 00 00 07 97 2D 78 2A 70 36 A0
					39 00 00 00 00 00 02 99 00
					//spr config
					39 00 00 40 00 00 04 FF 5A A5 14
					39 00 00 40 00 00 07 A3 00 04 00 04 70 80
					//LVD on
					39 00 00 00 00 00 04 FF 5A A5 05
					15 00 00 00 00 00 02 83 03
					15 00 00 00 00 00 02 84 03
					15 00 00 00 00 00 02 AA 94
					15 00 00 00 00 00 02 AB C9
					15 00 00 00 00 00 02 AC 05
					39 00 00 00 00 00 04 FF 5A A5 08
					15 00 00 00 00 00 02 B0 55
					39 00 00 00 00 00 04 FF 5A A5 1C
					39 00 00 00 00 00 03 FD 00 94
					15 00 00 00 00 00 02 E1 A2
					39 00 00 00 00 00 03 FD 00 00
					39 00 00 00 00 00 04 FF 5A A5 08
					15 00 00 00 00 00 02 B0 00
					//page 00
					39 00 00 00 00 00 04 FF 5A A5 00

					15 00 00 00 78 00 02 11 00

					15 00 00 00 14 00 02 29 00
				];
				oplus,dsi-aod-off-command = [
					39 00 00 40 00 00 04 FF 5A A5 08
					39 00 00 40 00 00 02 98 02
					39 00 00 40 00 00 04 FF 5A A5 4F
					39 00 00 40 00 00 02 81 06
					39 00 00 40 00 00 02 88 78
					39 00 00 40 00 00 04 FF 5A A5 05
					39 00 00 40 00 00 02 AE 94
					39 00 00 40 00 00 02 AF DF
					39 00 00 40 00 00 02 B1 9F
					39 00 00 40 00 00 02 B2 DF
					39 00 00 40 00 00 04 C2 2F 20 37
					39 00 00 40 00 00 03 C4 32 3E
					39 00 00 40 00 00 04 FF 5A A5 00
					39 00 00 40 00 00 02 38 00
					39 00 00 40 00 00 04 FF 5A A5 4F
					39 00 00 40 00 00 02 8A 78
					39 00 00 40 00 00 04 FF 5A A5 05
					39 00 00 40 00 00 02 AE 92
					39 00 00 40 00 00 02 AF DA
					39 00 00 40 00 00 02 B1 9B
					39 00 00 40 00 00 02 B2 DB
					39 00 00 40 00 00 04 C2 37 20 37
					39 00 00 40 00 00 03 C4 3E 3E
					39 00 00 40 00 00 04 FF 5A A5 08
					39 00 00 40 00 00 02 98 A6
					39 00 00 40 00 00 04 FF 5A A5 00
					39 00 00 40 00 00 02 00 00
					39 00 00 40 00 00 04 FF 5A A5 4F
					39 00 00 40 00 00 02 8B 78
					39 00 00 00 00 00 03 51 00 00

				];
				oplus,dsi-panel-aod-off-insert-black-command = [
					39 00 00 40 00 00 04 FF 5A A5 08
					39 00 00 40 00 00 02 98 02
					39 00 00 40 00 00 04 FF 5A A5 4F
					39 00 00 40 00 00 02 81 06
					39 00 00 40 00 00 02 88 78
					39 00 00 40 00 00 04 FF 5A A5 05
					39 00 00 40 00 00 02 AE 94
					39 00 00 40 00 00 02 AF DF
					39 00 00 40 00 00 02 B1 9F
					39 00 00 40 00 00 02 B2 DF
					39 00 00 40 00 00 04 C2 2F 20 37
					39 00 00 40 00 00 03 C4 32 3E
					39 00 00 40 00 00 04 FF 5A A5 00
					39 00 00 40 00 00 02 38 00
					39 00 00 40 00 00 04 FF 5A A5 4F
					39 00 00 40 00 00 02 8A 78
					39 00 00 40 00 00 04 FF 5A A5 05
					39 00 00 40 00 00 02 AE 92
					39 00 00 40 00 00 02 AF DA
					39 00 00 40 00 00 02 B1 9B
					39 00 00 40 00 00 02 B2 DB
					39 00 00 40 00 00 04 C2 37 20 37
					39 00 00 40 00 00 03 C4 3E 3E
					39 00 00 40 00 00 04 FF 5A A5 08
					39 00 00 40 00 00 02 98 A6
					39 00 00 40 00 00 04 FF 5A A5 00
					39 00 00 40 00 00 02 00 00
					39 00 00 40 00 00 04 FF 5A A5 4F
					39 00 00 40 00 00 02 8B 78
					39 00 00 00 00 00 03 51 00 00
				];
				oplus,dsi-lhbm-pressed-icon-on-command = [
					39 00 00 40 00 00 04 FF 5A A5 00
					39 00 00 40 00 00 02 6E 03
					39 00 00 00 00 00 07 2C 00 00 00 00 00 00
				];
				oplus,dsi-lhbm-pressed-icon-on-pwm-command = [

				];
				oplus,dsi-adfr-min-fps-120hz-command = [
					39 00 00 40 00 00 04 FF 5A A5 2D
					39 00 00 40 00 00 03 83 77 00
					15 00 00 40 00 00 02 97 03
					39 00 00 40 00 00 03 98 03 00
					39 00 00 40 00 00 03 99 0B 00
					39 00 00 40 00 00 03 9A 17 00
					39 00 00 40 00 00 03 9B 77 00
					39 00 00 40 00 00 05 A0 00 01 00 00
					39 00 00 40 00 00 05 A1 02 00 00 00
					39 00 00 40 00 00 03 83 00 00
					39 00 00 00 00 00 04 FF 5A A5 00
				];
				oplus,dsi-adfr-min-fps-30hz-command = [
					39 00 00 40 00 00 04 FF 5A A5 2D
					39 00 00 40 00 00 03 83 77 00
					15 00 00 40 00 00 02 97 03
					39 00 00 40 00 00 03 98 03 00
					39 00 00 40 00 00 03 99 0B 00
					39 00 00 40 00 00 03 9A 17 00
					39 00 00 40 00 00 03 9B 77 00
					39 00 00 40 00 00 05 A0 00 01 00 00
					39 00 00 40 00 00 05 A1 02 00 00 00
					39 00 00 40 00 00 03 83 03 00
					39 00 00 00 00 00 04 FF 5A A5 00
				];
				oplus,dsi-multi-te-enable-command = [
					39 00 00 40 00 00 04 FF 5A A5 01
					15 00 00 40 00 00 02 FB 08
					39 00 00 40 00 00 04 FF 5A A5 0A
					39 00 00 40 00 00 05 D8 00 21 00 80
					39 00 00 40 00 00 03 D9 0F 3C
					39 00 00 40 00 00 04 FF 5A A5 0B
					39 00 00 40 00 00 07 E9 00 1D 00 00 0F BA
					39 00 00 40 00 00 04 ED 80 00 08
					15 00 00 40 00 00 02 EE 03
					15 00 00 40 00 00 02 EF 7A
					39 00 00 40 00 00 09 F0 03 7A 00 00 00 00 00 00
					39 00 00 40 00 00 09 F1 00 6B 00 00 00 00 00 00
					39 00 00 40 00 00 04 FF 5A A5 20
					15 00 00 00 00 00 02 BB 96
				];
				oplus,dsi-multi-te-disable-command = [
					39 00 00 40 00 00 04 FF 5A A5 20
					39 00 00 00 00 00 02 BB 06
				];

				oplus,dsi-timing-switch-command-state = "dsi_hs_mode";
				oplus,dsi-pwm-switch-1to3pul-command-state = "dsi_hs_mode";
				oplus,dsi-pwm-switch-1to18pul-command-state = "dsi_hs_mode";
				oplus,dsi-pwm-switch-18to3pul-command-state = "dsi_hs_mode";
				oplus,dsi-pwm-switch-3to18pul-command-state = "dsi_hs_mode";
				oplus,dsi-timing-switch-1pulse-command-state = "dsi_hs_mode";
				oplus,dsi-pwm-switch-3to1pul-command-state = "dsi_hs_mode";
				oplus,dsi-pwm-switch-18to1pul-command-state = "dsi_hs_mode";
				oplus,dsi-on-command-state = "dsi_lp_mode";
				oplus,dsi-on-t0-command-state = "dsi_lp_mode";
				oplus,dsi-aod-off-command-state = "dsi_ls_mode";
				oplus,dsi-panel-aod-off-insert-black-command-state = "dsi_ls_mode";
				oplus,dsi-lhbm-pressed-icon-on-command-state = "dsi_hs_mode";
				oplus,dsi-lhbm-pressed-icon-on-pwm-command-state = "dsi_hs_mode";
				oplus,dsi-adfr-min-fps-120hz-command-state = "dsi_hs_mode";
				oplus,dsi-adfr-min-fps-30hz-command-state = "dsi_hs_mode";
				oplus,dsi-multi-te-enable-command-state = "dsi_hs_mode";
				oplus,dsi-multi-te-disable-command-state = "dsi_hs_mode";

				oplus,dsc-params-entries = <&dsc_params>;
/*				oplus,phy-timcon {
					hs-trail = <14>;
					clk-trail = <15>;
				};*/
				oplus,dyn-fps {
					switch_en = <1>;
					vact_timing_fps = <120>;
					apollo_limit_superior_us = <4900>;
					apollo_limit_inferior_us = <6750>;
					apollo_transfer_time_us = <6200>;
				};
				oplus,display-mode {
					oplus,display-mode@0 {
						hdisplay = <1272>;
						vdisplay = <2772>;
/*						fhd-hfp = <9>;
						fhd-hsa = <2>;
						fhd-hbp = <21>;
						fhd-vfp = <52>;
						fhd-vsa = <14>;
						fhd-vbp = <22>;*/
						hskew = <OPLUS_ADFR>;
					};
					oplus,display-mode@1 {
						hdisplay = <1080>;
						vdisplay = <2354>;
/*						fhd-hfp = <9>;
						fhd-hsa = <2>;
						fhd-hbp = <21>;
						fhd-vfp = <52>;
						fhd-vsa = <14>;
						fhd-vbp = <22>;*/
						hskew = <OPLUS_ADFR>;
					};
				};
			};
		};
	};
};

&ac330_p_3_a0020_dsi_cmd_panel {
	oplus,dsi-display-panel@0 {
		res-switch = <2>;
		/* Hardware config */
		oplus,panel-supply-entries = <&dsi_panel_pwr_supply>;
		oplus,panel-power-on-sequence = "1", "vddio", "5", "pmic_reset", "1", "vddr", "5", "vci", "1";
		oplus,panel-power-off-sequence = "2", "vci", "5", "vddr", "0", "vddio", "5", "pmic_reset", "1";
		reset-gpios = <&pio 41 0>;
		oplus,panel-reset-sequence = <2 10>, <1 1>, <0 1>, <1 20>;
		/* Panel config */
		oplus,dsi-serial-number-enabled=<1>;
		oplus,dsi-serial-number-switch-page;
		oplus,dsi-serial-number-index= <0>;
		oplus,dsi-serial-number-switch-page-command = <0xFF 0x5A 0xA5 0x1D>;
		oplus,dsi-serial-number-default-switch-page-command = <0xFF 0x5A 0xA5 0x00>;
		oplus,dsi-serial-number-reg= <0x80>;
		oplus,dsi-serial-number-read-count= <7>;
		oplus,dsi-serial-number-year-offset= <9>;
		oplus,mode-switch-h2l-delay;
		oplus,backlight-check-disable;
		/* demura */
		//oplus,demura-dbv-enable;
		//oplus,demura-dbv-cfg = <1153 4095>;
		/*color*/
		oplus,color-vivid-status;
		oplus,color-srgb-status;
		// oplus,color-softiris-status;
		// oplus,color-dual-panel-status;
		oplus,color-dual-brightness-status;
		oplus,color-oplus-calibrate-status;
		// oplus,color-samsung-status;
		oplus,color-loading-status;
		//oplus,color-2nit-status;
		// oplus,color-nature-profession-status;
		/* ESD */
		oplus,cust-esd-check = <0>; //both check TE and reg
		oplus,esd-check-enable = <1>;
		oplus,esd_check_cmd = [
			0A
		];
		oplus,esd_check_count = [
			01
		];
		oplus,esd_check_value = [
			9C
		];
		oplus,esd_check_mask = [
			FF
		];
		/* ext_params */
		oplus,panel-type = <2>;
		oplus,keep_ulps = <1>;
		oplus,lane-swap-en = <0>;
		oplus,lane-swap = <
			MIPITX_PHY_LANE_0 MIPITX_PHY_LANE_1 MIPITX_PHY_LANE_3 MIPITX_PHY_LANE_2 MIPITX_PHY_LANE_CK MIPITX_PHY_LANE_RX
			MIPITX_PHY_LANE_0 MIPITX_PHY_LANE_1 MIPITX_PHY_LANE_3 MIPITX_PHY_LANE_2 MIPITX_PHY_LANE_CK MIPITX_PHY_LANE_RX
		>;
		oplus,lcm-color-mode = <MTK_DRM_COLOR_MODE_DISPLAY_P3>;
		oplus,output-mode = <MTK_PANEL_DSC_SINGLE_PORT>;
		oplus,panel-bpp = <10>;
		oplus,physical-width-um = <71868>;
		oplus,physical-height-um = <156618>;

		/*adfr config*/
		oplus-adfr-config = <0x201>;
		oplus-adfr-test-te-gpios = <&pio 42 0>;

		/* OFP config */
		oplus,ofp-fp-type = <0x410>;
		oplus,ofp-fp-local-hbm-calibration;
		oplus,ofp-longrui-aod-config = <0x06>;
		//oplus,ofp-need-aod-off-insert-black-frame;
		/*pwm config*/
		//oplus,pwm-turbo-support = <1>;
		//oplus,pwm-switch-backlight-threshold = <1162>;
		//oplus,pwm-aid-switch-enable;
		//oplus,pwm-onepulse-support = <1>;
		//oplus,pwm-onepulse-enabled = <0>;
		//oplus,pwm-turbo-wait-te = <1>;
	};
};
